AUTOSAR XML (schema 4-2-2)
package /STELLANTIS/EPT/ASWCs
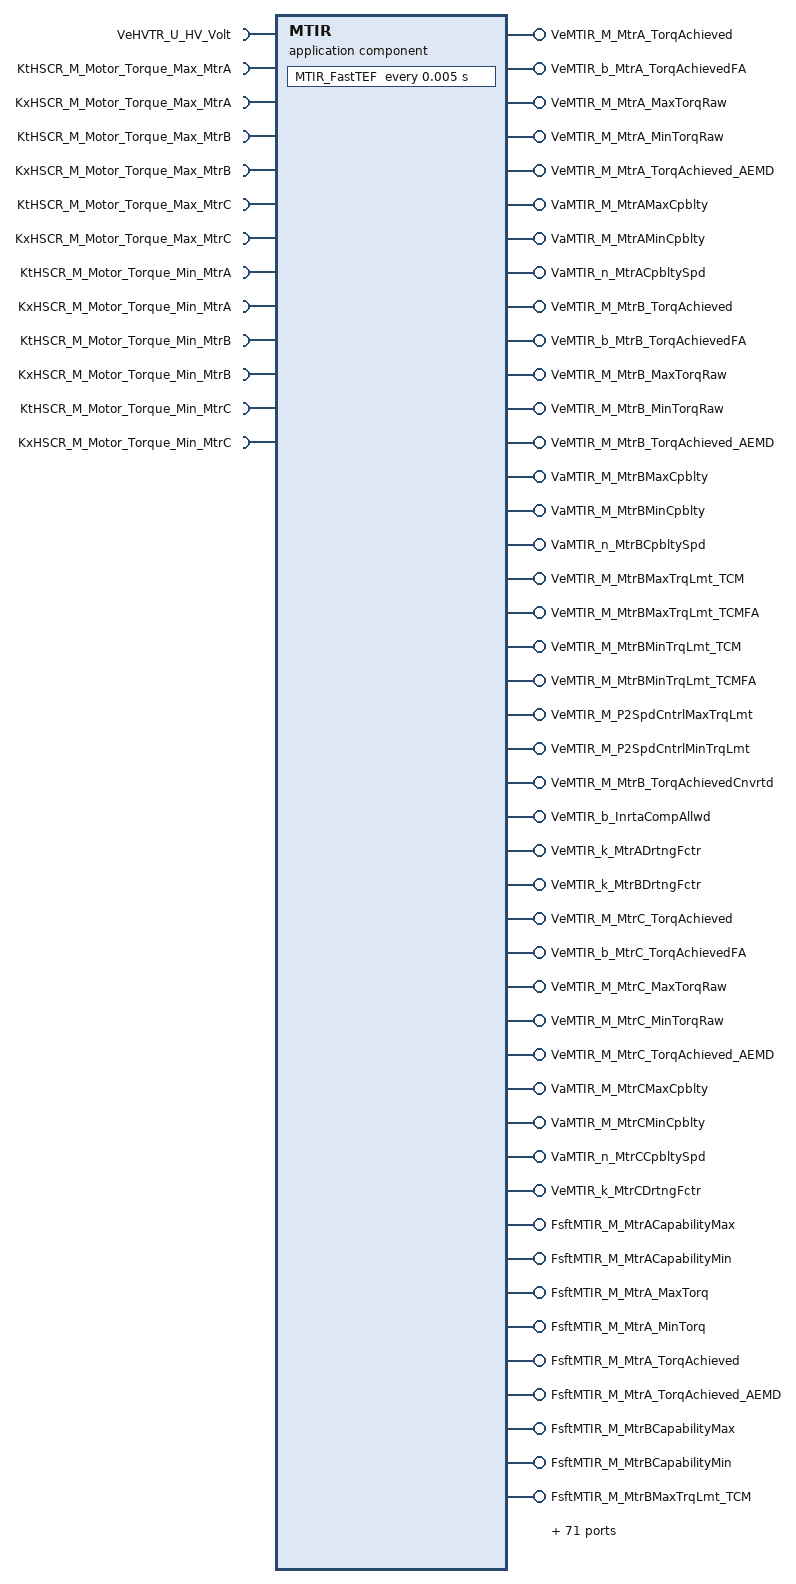
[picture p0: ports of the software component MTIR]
  application sw component type MTIR
    require port VeHVTR_U_HV_Volt: nonqueued-receiver-com-spec{data-element=Value, init-value=0}, required-interface=VeHVTR_U_HV_Volt
    115 x provide port:
      VeMTIR_M_MtrA_TorqAchieved: nonqueued-sender-com-spec{data-element=Value, init-value=0}, provided-interface=VeMTIR_M_MtrA_TorqAchieved
      VeMTIR_b_MtrA_TorqAchievedFA: nonqueued-sender-com-spec{data-element=Value, init-value=0}, provided-interface=VeMTIR_b_MtrA_TorqAchievedFA
      VeMTIR_M_MtrA_MaxTorqRaw: nonqueued-sender-com-spec{data-element=Value, init-value=0}, provided-interface=VeMTIR_M_MtrA_MaxTorqRaw
      VeMTIR_M_MtrA_MinTorqRaw: nonqueued-sender-com-spec{data-element=Value, init-value=0}, provided-interface=VeMTIR_M_MtrA_MinTorqRaw
      VeMTIR_M_MtrA_TorqAchieved_AEMD: nonqueued-sender-com-spec{data-element=Value, init-value=0}, provided-interface=VeMTIR_M_MtrA_TorqAchieved_AEMD
      VaMTIR_M_MtrAMaxCpblty: nonqueued-sender-com-spec{data-element=Value, init-value=16 x 0}, provided-interface=VaMTIR_M_MtrAMaxCpblty
      VaMTIR_M_MtrAMinCpblty: nonqueued-sender-com-spec{data-element=Value, init-value=16 x 0}, provided-interface=VaMTIR_M_MtrAMinCpblty
      VaMTIR_n_MtrACpbltySpd: nonqueued-sender-com-spec{data-element=Value, init-value=16 x 0}, provided-interface=VaMTIR_n_MtrACpbltySpd
      VeMTIR_M_MtrB_TorqAchieved: nonqueued-sender-com-spec{data-element=Value, init-value=0}, provided-interface=VeMTIR_M_MtrB_TorqAchieved
      VeMTIR_b_MtrB_TorqAchievedFA: nonqueued-sender-com-spec{data-element=Value, init-value=0}, provided-interface=VeMTIR_b_MtrB_TorqAchievedFA
      VeMTIR_M_MtrB_MaxTorqRaw: nonqueued-sender-com-spec{data-element=Value, init-value=0}, provided-interface=VeMTIR_M_MtrB_MaxTorqRaw
      VeMTIR_M_MtrB_MinTorqRaw: nonqueued-sender-com-spec{data-element=Value, init-value=0}, provided-interface=VeMTIR_M_MtrB_MinTorqRaw
      VeMTIR_M_MtrB_TorqAchieved_AEMD: nonqueued-sender-com-spec{data-element=Value, init-value=0}, provided-interface=VeMTIR_M_MtrB_TorqAchieved_AEMD
      VaMTIR_M_MtrBMaxCpblty: nonqueued-sender-com-spec{data-element=Value, init-value=16 x 0}, provided-interface=VaMTIR_M_MtrBMaxCpblty
      VaMTIR_M_MtrBMinCpblty: nonqueued-sender-com-spec{data-element=Value, init-value=16 x 0}, provided-interface=VaMTIR_M_MtrBMinCpblty
      VaMTIR_n_MtrBCpbltySpd: nonqueued-sender-com-spec{data-element=Value, init-value=16 x 0}, provided-interface=VaMTIR_n_MtrBCpbltySpd
      VeMTIR_M_MtrBMaxTrqLmt_TCM: nonqueued-sender-com-spec{data-element=Value, init-value=0}, provided-interface=VeMTIR_M_MtrBMaxTrqLmt_TCM
      VeMTIR_M_MtrBMaxTrqLmt_TCMFA: nonqueued-sender-com-spec{data-element=Value, init-value=0}, provided-interface=VeMTIR_M_MtrBMaxTrqLmt_TCMFA
      VeMTIR_M_MtrBMinTrqLmt_TCM: nonqueued-sender-com-spec{data-element=Value, init-value=0}, provided-interface=VeMTIR_M_MtrBMinTrqLmt_TCM
      VeMTIR_M_MtrBMinTrqLmt_TCMFA: nonqueued-sender-com-spec{data-element=Value, init-value=0}, provided-interface=VeMTIR_M_MtrBMinTrqLmt_TCMFA
      VeMTIR_M_P2SpdCntrlMaxTrqLmt: nonqueued-sender-com-spec{data-element=Value, init-value=0}, provided-interface=VeMTIR_M_P2SpdCntrlMaxTrqLmt
      VeMTIR_M_P2SpdCntrlMinTrqLmt: nonqueued-sender-com-spec{data-element=Value, init-value=0}, provided-interface=VeMTIR_M_P2SpdCntrlMinTrqLmt
      VeMTIR_M_MtrB_TorqAchievedCnvrtd: nonqueued-sender-com-spec{data-element=Value, init-value=0}, provided-interface=VeMTIR_M_MtrB_TorqAchievedCnvrtd
      VeMTIR_b_InrtaCompAllwd: nonqueued-sender-com-spec{data-element=Value, init-value=0}, provided-interface=VeMTIR_b_InrtaCompAllwd
      VeMTIR_k_MtrADrtngFctr: nonqueued-sender-com-spec{data-element=Value, init-value=0}, provided-interface=VeMTIR_k_MtrADrtngFctr
      VeMTIR_k_MtrBDrtngFctr: nonqueued-sender-com-spec{data-element=Value, init-value=0}, provided-interface=VeMTIR_k_MtrBDrtngFctr
      VeMTIR_M_MtrC_TorqAchieved: nonqueued-sender-com-spec{data-element=Value, init-value=0}, provided-interface=VeMTIR_M_MtrC_TorqAchieved
      VeMTIR_b_MtrC_TorqAchievedFA: nonqueued-sender-com-spec{data-element=Value, init-value=0}, provided-interface=VeMTIR_b_MtrC_TorqAchievedFA
      VeMTIR_M_MtrC_MaxTorqRaw: nonqueued-sender-com-spec{data-element=Value, init-value=0}, provided-interface=VeMTIR_M_MtrC_MaxTorqRaw
      VeMTIR_M_MtrC_MinTorqRaw: nonqueued-sender-com-spec{data-element=Value, init-value=0}, provided-interface=VeMTIR_M_MtrC_MinTorqRaw
      VeMTIR_M_MtrC_TorqAchieved_AEMD: nonqueued-sender-com-spec{data-element=Value, init-value=0}, provided-interface=VeMTIR_M_MtrC_TorqAchieved_AEMD
      VaMTIR_M_MtrCMaxCpblty: nonqueued-sender-com-spec{data-element=Value, init-value=16 x 0}, provided-interface=VaMTIR_M_MtrCMaxCpblty
      VaMTIR_M_MtrCMinCpblty: nonqueued-sender-com-spec{data-element=Value, init-value=16 x 0}, provided-interface=VaMTIR_M_MtrCMinCpblty
      VaMTIR_n_MtrCCpbltySpd: nonqueued-sender-com-spec{data-element=Value, init-value=16 x 0}, provided-interface=VaMTIR_n_MtrCCpbltySpd
      VeMTIR_k_MtrCDrtngFctr: nonqueued-sender-com-spec{data-element=Value, init-value=0}, provided-interface=VeMTIR_k_MtrCDrtngFctr
      FsftMTIR_M_MtrACapabilityMax: server-com-spec=FsftMTIR_M_MtrACapabilityMax, provided-interface=FsftMTIR_M_MtrACapabilityMax
      FsftMTIR_M_MtrACapabilityMin: server-com-spec=FsftMTIR_M_MtrACapabilityMin, provided-interface=FsftMTIR_M_MtrACapabilityMin
      FsftMTIR_M_MtrA_MaxTorq: server-com-spec=FsftMTIR_M_MtrA_MaxTorq, provided-interface=FsftMTIR_M_MtrA_MaxTorq
      FsftMTIR_M_MtrA_MinTorq: server-com-spec=FsftMTIR_M_MtrA_MinTorq, provided-interface=FsftMTIR_M_MtrA_MinTorq
      FsftMTIR_M_MtrA_TorqAchieved: server-com-spec=FsftMTIR_M_MtrA_TorqAchieved, provided-interface=FsftMTIR_M_MtrA_TorqAchieved
      FsftMTIR_M_MtrA_TorqAchieved_AEMD: server-com-spec=FsftMTIR_M_MtrA_TorqAchieved_AEMD, provided-interface=FsftMTIR_M_MtrA_TorqAchieved_AEMD
      FsftMTIR_M_MtrBCapabilityMax: server-com-spec=FsftMTIR_M_MtrBCapabilityMax, provided-interface=FsftMTIR_M_MtrBCapabilityMax
      FsftMTIR_M_MtrBCapabilityMin: server-com-spec=FsftMTIR_M_MtrBCapabilityMin, provided-interface=FsftMTIR_M_MtrBCapabilityMin
      FsftMTIR_M_MtrBMaxTrqLmt_TCM: server-com-spec=FsftMTIR_M_MtrBMaxTrqLmt_TCM, provided-interface=FsftMTIR_M_MtrBMaxTrqLmt_TCM
      FsftMTIR_M_MtrBMinTrqLmt_TCM: server-com-spec=FsftMTIR_M_MtrBMinTrqLmt_TCM, provided-interface=FsftMTIR_M_MtrBMinTrqLmt_TCM
      FsftMTIR_M_MtrB_MaxTorq: server-com-spec=FsftMTIR_M_MtrB_MaxTorq, provided-interface=FsftMTIR_M_MtrB_MaxTorq
      FsftMTIR_M_MtrB_MinTorq: server-com-spec=FsftMTIR_M_MtrB_MinTorq, provided-interface=FsftMTIR_M_MtrB_MinTorq
      FsftMTIR_M_MtrB_TorqAchieved: server-com-spec=FsftMTIR_M_MtrB_TorqAchieved, provided-interface=FsftMTIR_M_MtrB_TorqAchieved
      FsftMTIR_M_MtrB_TorqAchieved_AEMD: server-com-spec=FsftMTIR_M_MtrB_TorqAchieved_AEMD, provided-interface=FsftMTIR_M_MtrB_TorqAchieved_AEMD
      FsftMTIR_M_MtrCCapabilityMax: server-com-spec=FsftMTIR_M_MtrCCapabilityMax, provided-interface=FsftMTIR_M_MtrCCapabilityMax
      FsftMTIR_M_MtrCCapabilityMin: server-com-spec=FsftMTIR_M_MtrCCapabilityMin, provided-interface=FsftMTIR_M_MtrCCapabilityMin
      FsftMTIR_M_MtrC_MaxTorq: server-com-spec=FsftMTIR_M_MtrC_MaxTorq, provided-interface=FsftMTIR_M_MtrC_MaxTorq
      FsftMTIR_M_MtrC_MinTorq: server-com-spec=FsftMTIR_M_MtrC_MinTorq, provided-interface=FsftMTIR_M_MtrC_MinTorq
      FsftMTIR_M_MtrC_TorqAchieved: server-com-spec=FsftMTIR_M_MtrC_TorqAchieved, provided-interface=FsftMTIR_M_MtrC_TorqAchieved
      FsftMTIR_M_MtrC_TorqAchieved_AEMD: server-com-spec=FsftMTIR_M_MtrC_TorqAchieved_AEMD, provided-interface=FsftMTIR_M_MtrC_TorqAchieved_AEMD
      FsftMTIR_M_P2SpdCntrlMaxTrqLmt: server-com-spec=FsftMTIR_M_P2SpdCntrlMaxTrqLmt, provided-interface=FsftMTIR_M_P2SpdCntrlMaxTrqLmt
      FsftMTIR_M_P2SpdCntrlMinTrqLmt: server-com-spec=FsftMTIR_M_P2SpdCntrlMinTrqLmt, provided-interface=FsftMTIR_M_P2SpdCntrlMinTrqLmt
      FsftMTIR_k_MtrADeratingFactor: server-com-spec=FsftMTIR_k_MtrADeratingFactor, provided-interface=FsftMTIR_k_MtrADeratingFactor
      FsftMTIR_k_MtrBDeratingFactor: server-com-spec=FsftMTIR_k_MtrBDeratingFactor, provided-interface=FsftMTIR_k_MtrBDeratingFactor
      FsftMTIR_k_MtrCDeratingFactor: server-com-spec=FsftMTIR_k_MtrCDeratingFactor, provided-interface=FsftMTIR_k_MtrCDeratingFactor
      FsftMTIR_n_MtrACapabilitySpd: server-com-spec=FsftMTIR_n_MtrACapabilitySpd, provided-interface=FsftMTIR_n_MtrACapabilitySpd
      FsftMTIR_n_MtrBCapabilitySpd: server-com-spec=FsftMTIR_n_MtrBCapabilitySpd, provided-interface=FsftMTIR_n_MtrBCapabilitySpd
      FsftMTIR_n_MtrCCapabilitySpd: server-com-spec=FsftMTIR_n_MtrCCapabilitySpd, provided-interface=FsftMTIR_n_MtrCCapabilitySpd
      PokeMTIR_M_MtrACapabilityMax: server-com-spec{operation=PokeMTIR_M_MtrACapabilityMax, queue-length=1}, provided-interface=PokeMTIR_M_MtrACapabilityMax
      PokeMTIR_M_MtrACapabilityMin: server-com-spec{operation=PokeMTIR_M_MtrACapabilityMin, queue-length=1}, provided-interface=PokeMTIR_M_MtrACapabilityMin
      PokeMTIR_M_MtrA_MaxTorq: server-com-spec{operation=PokeMTIR_M_MtrA_MaxTorq, queue-length=1}, provided-interface=PokeMTIR_M_MtrA_MaxTorq
      PokeMTIR_M_MtrA_MinTorq: server-com-spec{operation=PokeMTIR_M_MtrA_MinTorq, queue-length=1}, provided-interface=PokeMTIR_M_MtrA_MinTorq
      PokeMTIR_M_MtrA_TorqAchieved: server-com-spec{operation=PokeMTIR_M_MtrA_TorqAchieved, queue-length=1}, provided-interface=PokeMTIR_M_MtrA_TorqAchieved
      PokeMTIR_M_MtrA_TorqAchieved_AEMD: server-com-spec{operation=PokeMTIR_M_MtrA_TorqAchieved_AEMD, queue-length=1}, provided-interface=PokeMTIR_M_MtrA_TorqAchieved_AEMD
      PokeMTIR_M_MtrBCapabilityMax: server-com-spec{operation=PokeMTIR_M_MtrBCapabilityMax, queue-length=1}, provided-interface=PokeMTIR_M_MtrBCapabilityMax
      PokeMTIR_M_MtrBCapabilityMin: server-com-spec{operation=PokeMTIR_M_MtrBCapabilityMin, queue-length=1}, provided-interface=PokeMTIR_M_MtrBCapabilityMin
      PokeMTIR_M_MtrBMaxTrqLmt_TCM: server-com-spec{operation=PokeMTIR_M_MtrBMaxTrqLmt_TCM, queue-length=1}, provided-interface=PokeMTIR_M_MtrBMaxTrqLmt_TCM
      PokeMTIR_M_MtrBMinTrqLmt_TCM: server-com-spec{operation=PokeMTIR_M_MtrBMinTrqLmt_TCM, queue-length=1}, provided-interface=PokeMTIR_M_MtrBMinTrqLmt_TCM
      PokeMTIR_M_MtrB_MaxTorq: server-com-spec{operation=PokeMTIR_M_MtrB_MaxTorq, queue-length=1}, provided-interface=PokeMTIR_M_MtrB_MaxTorq
      PokeMTIR_M_MtrB_MinTorq: server-com-spec{operation=PokeMTIR_M_MtrB_MinTorq, queue-length=1}, provided-interface=PokeMTIR_M_MtrB_MinTorq
      PokeMTIR_M_MtrB_TorqAchieved: server-com-spec{operation=PokeMTIR_M_MtrB_TorqAchieved, queue-length=1}, provided-interface=PokeMTIR_M_MtrB_TorqAchieved
      PokeMTIR_M_MtrB_TorqAchieved_AEMD: server-com-spec{operation=PokeMTIR_M_MtrB_TorqAchieved_AEMD, queue-length=1}, provided-interface=PokeMTIR_M_MtrB_TorqAchieved_AEMD
      PokeMTIR_M_MtrCCapabilityMax: server-com-spec{operation=PokeMTIR_M_MtrCCapabilityMax, queue-length=1}, provided-interface=PokeMTIR_M_MtrCCapabilityMax
      PokeMTIR_M_MtrCCapabilityMin: server-com-spec{operation=PokeMTIR_M_MtrCCapabilityMin, queue-length=1}, provided-interface=PokeMTIR_M_MtrCCapabilityMin
      PokeMTIR_M_MtrC_MaxTorq: server-com-spec{operation=PokeMTIR_M_MtrC_MaxTorq, queue-length=1}, provided-interface=PokeMTIR_M_MtrC_MaxTorq
      PokeMTIR_M_MtrC_MinTorq: server-com-spec{operation=PokeMTIR_M_MtrC_MinTorq, queue-length=1}, provided-interface=PokeMTIR_M_MtrC_MinTorq
      PokeMTIR_M_MtrC_TorqAchieved: server-com-spec{operation=PokeMTIR_M_MtrC_TorqAchieved, queue-length=1}, provided-interface=PokeMTIR_M_MtrC_TorqAchieved
      PokeMTIR_M_MtrC_TorqAchieved_AEMD: server-com-spec{operation=PokeMTIR_M_MtrC_TorqAchieved_AEMD, queue-length=1}, provided-interface=PokeMTIR_M_MtrC_TorqAchieved_AEMD
      PokeMTIR_M_P2SpdCntrlMaxTrqLmt: server-com-spec{operation=PokeMTIR_M_P2SpdCntrlMaxTrqLmt, queue-length=1}, provided-interface=PokeMTIR_M_P2SpdCntrlMaxTrqLmt
      PokeMTIR_M_P2SpdCntrlMinTrqLmt: server-com-spec{operation=PokeMTIR_M_P2SpdCntrlMinTrqLmt, queue-length=1}, provided-interface=PokeMTIR_M_P2SpdCntrlMinTrqLmt
      PokeMTIR_k_MtrADeratingFactor: server-com-spec{operation=PokeMTIR_k_MtrADeratingFactor, queue-length=1}, provided-interface=PokeMTIR_k_MtrADeratingFactor
      PokeMTIR_k_MtrBDeratingFactor: server-com-spec{operation=PokeMTIR_k_MtrBDeratingFactor, queue-length=1}, provided-interface=PokeMTIR_k_MtrBDeratingFactor
      PokeMTIR_k_MtrCDeratingFactor: server-com-spec{operation=PokeMTIR_k_MtrCDeratingFactor, queue-length=1}, provided-interface=PokeMTIR_k_MtrCDeratingFactor
      PokeMTIR_n_MtrACapabilitySpd: server-com-spec{operation=PokeMTIR_n_MtrACapabilitySpd, queue-length=1}, provided-interface=PokeMTIR_n_MtrACapabilitySpd
      PokeMTIR_n_MtrBCapabilitySpd: server-com-spec{operation=PokeMTIR_n_MtrBCapabilitySpd, queue-length=1}, provided-interface=PokeMTIR_n_MtrBCapabilitySpd
      PokeMTIR_n_MtrCCapabilitySpd: server-com-spec{operation=PokeMTIR_n_MtrCCapabilitySpd, queue-length=1}, provided-interface=PokeMTIR_n_MtrCCapabilitySpd
      TmotMTIR_M_MtrACapabilityMax: server-com-spec=TmotMTIR_M_MtrACapabilityMax, provided-interface=TmotMTIR_M_MtrACapabilityMax
      TmotMTIR_M_MtrACapabilityMin: server-com-spec=TmotMTIR_M_MtrACapabilityMin, provided-interface=TmotMTIR_M_MtrACapabilityMin
      TmotMTIR_M_MtrBCapabilityMax: server-com-spec=TmotMTIR_M_MtrBCapabilityMax, provided-interface=TmotMTIR_M_MtrBCapabilityMax
      TmotMTIR_M_MtrBCapabilityMin: server-com-spec=TmotMTIR_M_MtrBCapabilityMin, provided-interface=TmotMTIR_M_MtrBCapabilityMin
      TmotMTIR_M_MtrCCapabilityMax: server-com-spec=TmotMTIR_M_MtrCCapabilityMax, provided-interface=TmotMTIR_M_MtrCCapabilityMax
      TmotMTIR_M_MtrCCapabilityMin: server-com-spec=TmotMTIR_M_MtrCCapabilityMin, provided-interface=TmotMTIR_M_MtrCCapabilityMin
      TmotMTIR_b_MtrA_MaxTorq: server-com-spec=TmotMTIR_b_MtrA_MaxTorq, provided-interface=TmotMTIR_b_MtrA_MaxTorq
      TmotMTIR_b_MtrA_MinTorq: server-com-spec=TmotMTIR_b_MtrA_MinTorq, provided-interface=TmotMTIR_b_MtrA_MinTorq
      TmotMTIR_b_MtrA_TorqAchieved: server-com-spec=TmotMTIR_b_MtrA_TorqAchieved, provided-interface=TmotMTIR_b_MtrA_TorqAchieved
      TmotMTIR_b_MtrA_TorqAchieved_AEMD: server-com-spec=TmotMTIR_b_MtrA_TorqAchieved_AEMD, provided-interface=TmotMTIR_b_MtrA_TorqAchieved_AEMD
      TmotMTIR_b_MtrB_MaxTorq: server-com-spec=TmotMTIR_b_MtrB_MaxTorq, provided-interface=TmotMTIR_b_MtrB_MaxTorq
      TmotMTIR_b_MtrB_MinTorq: server-com-spec=TmotMTIR_b_MtrB_MinTorq, provided-interface=TmotMTIR_b_MtrB_MinTorq
      TmotMTIR_b_MtrB_TorqAchieved: server-com-spec=TmotMTIR_b_MtrB_TorqAchieved, provided-interface=TmotMTIR_b_MtrB_TorqAchieved
      TmotMTIR_b_MtrB_TorqAchieved_AEMD: server-com-spec=TmotMTIR_b_MtrB_TorqAchieved_AEMD, provided-interface=TmotMTIR_b_MtrB_TorqAchieved_AEMD
      TmotMTIR_b_MtrC_MaxTorq: server-com-spec=TmotMTIR_b_MtrC_MaxTorq, provided-interface=TmotMTIR_b_MtrC_MaxTorq
      TmotMTIR_b_MtrC_MinTorq: server-com-spec=TmotMTIR_b_MtrC_MinTorq, provided-interface=TmotMTIR_b_MtrC_MinTorq
      TmotMTIR_b_MtrC_TorqAchieved: server-com-spec=TmotMTIR_b_MtrC_TorqAchieved, provided-interface=TmotMTIR_b_MtrC_TorqAchieved
      TmotMTIR_b_MtrC_TorqAchieved_AEMD: server-com-spec=TmotMTIR_b_MtrC_TorqAchieved_AEMD, provided-interface=TmotMTIR_b_MtrC_TorqAchieved_AEMD
      TmotMTIR_k_MtrADeratingFactor: server-com-spec=TmotMTIR_k_MtrADeratingFactor, provided-interface=TmotMTIR_k_MtrADeratingFactor
      TmotMTIR_k_MtrBDeratingFactor: server-com-spec=TmotMTIR_k_MtrBDeratingFactor, provided-interface=TmotMTIR_k_MtrBDeratingFactor
      TmotMTIR_k_MtrCDeratingFactor: server-com-spec=TmotMTIR_k_MtrCDeratingFactor, provided-interface=TmotMTIR_k_MtrCDeratingFactor
      TmotMTIR_n_MtrACapabilitySpd: server-com-spec=TmotMTIR_n_MtrACapabilitySpd, provided-interface=TmotMTIR_n_MtrACapabilitySpd
      TmotMTIR_n_MtrBCapabilitySpd: server-com-spec=TmotMTIR_n_MtrBCapabilitySpd, provided-interface=TmotMTIR_n_MtrBCapabilitySpd
      TmotMTIR_n_MtrCCapabilitySpd: server-com-spec=TmotMTIR_n_MtrCCapabilitySpd, provided-interface=TmotMTIR_n_MtrCCapabilitySpd
    12 x require port:
      KtHSCR_M_Motor_Torque_Max_MtrA: parameter-require-com-spec{init-value=[252 252 252 252 252 252 244.990005493164 201.789993286133 165.270004272461 139.75 120.849998474121 105.48999786377 94.379997253418 84.9199981689453 76.5400009155273 70.5100021362305 65.2399978637695 60.5299987792969 56.2400016784668 52.3600006103516 49.0099983215332 46], parameter=KtHSCR_M_Motor_Torque_Max_MtrA}, required-interface=KtHSCR_M_Motor_Torque_Max_MtrA
      KxHSCR_M_Motor_Torque_Max_MtrA: parameter-require-com-spec{init-value=[0.00999999977648258 500 1000 1500 2000 2500 3000 3500 4000 4500 5000 5500 6000 6500 7000 7500 8000 8500 9000 9500 10000 10500], parameter=KxHSCR_M_Motor_Torque_Max_MtrA}, required-interface=KxHSCR_M_Motor_Torque_Max_MtrA
      KtHSCR_M_Motor_Torque_Max_MtrB: parameter-require-com-spec{init-value=[252 252 252 252 252 252 244.990005493164 201.789993286133 165.270004272461 139.75 120.849998474121 105.48999786377 94.379997253418 84.9199981689453 76.5400009155273 70.5100021362305 65.2399978637695 60.5299987792969 56.2400016784668 52.3600006103516 49.0099983215332 46], parameter=KtHSCR_M_Motor_Torque_Max_MtrB}, required-interface=KtHSCR_M_Motor_Torque_Max_MtrB
      KxHSCR_M_Motor_Torque_Max_MtrB: parameter-require-com-spec{init-value=[0.00999999977648258 500 1000 1500 2000 2500 3000 3500 4000 4500 5000 5500 6000 6500 7000 7500 8000 8500 9000 9500 10000 10500], parameter=KxHSCR_M_Motor_Torque_Max_MtrB}, required-interface=KxHSCR_M_Motor_Torque_Max_MtrB
      KtHSCR_M_Motor_Torque_Max_MtrC: parameter-require-com-spec{init-value=[252 252 252 252 252 252 244.990005493164 201.789993286133 165.270004272461 139.75 120.849998474121 105.48999786377 94.379997253418 84.9199981689453 76.5400009155273 70.5100021362305 65.2399978637695 60.5299987792969 56.2400016784668 52.3600006103516 49.0099983215332 46], parameter=KtHSCR_M_Motor_Torque_Max_MtrC}, required-interface=KtHSCR_M_Motor_Torque_Max_MtrC
      KxHSCR_M_Motor_Torque_Max_MtrC: parameter-require-com-spec{init-value=[0.00999999977648258 500 1000 1500 2000 2500 3000 3500 4000 4500 5000 5500 6000 6500 7000 7500 8000 8500 9000 9500 10000 10500], parameter=KxHSCR_M_Motor_Torque_Max_MtrC}, required-interface=KxHSCR_M_Motor_Torque_Max_MtrC
      KtHSCR_M_Motor_Torque_Min_MtrA: parameter-require-com-spec{init-value=[-252 -252 -252 -252 -252 -252 -252 -238.029998779297 -205.229995727539 -175.800003051758 -152.279998779297 -133.940002441406 -119.400001525879 -107.589996337891 -97.8499984741211 -89.6699981689453 -82.7399978637695 -76.7900009155273 -71.629997253418 -67.1100006103516 -63.0999984741211 -60], parameter=KtHSCR_M_Motor_Torque_Min_MtrA}, required-interface=KtHSCR_M_Motor_Torque_Min_MtrA
      KxHSCR_M_Motor_Torque_Min_MtrA: parameter-require-com-spec{init-value=[0.00999999977648258 500 1000 1500 2000 2500 3000 3500 4000 4500 5000 5500 6000 6500 7000 7500 8000 8500 9000 9500 10000 10500], parameter=KxHSCR_M_Motor_Torque_Min_MtrA}, required-interface=KxHSCR_M_Motor_Torque_Min_MtrA
      KtHSCR_M_Motor_Torque_Min_MtrB: parameter-require-com-spec{init-value=[-252 -252 -252 -252 -252 -252 -252 -238.029998779297 -205.229995727539 -175.800003051758 -152.279998779297 -133.940002441406 -119.400001525879 -107.589996337891 -97.8499984741211 -89.6699981689453 -82.7399978637695 -76.7900009155273 -71.629997253418 -67.1100006103516 -63.0999984741211 -60], parameter=KtHSCR_M_Motor_Torque_Min_MtrB}, required-interface=KtHSCR_M_Motor_Torque_Min_MtrB
      KxHSCR_M_Motor_Torque_Min_MtrB: parameter-require-com-spec{init-value=[0.00999999977648258 500 1000 1500 2000 2500 3000 3500 4000 4500 5000 5500 6000 6500 7000 7500 8000 8500 9000 9500 10000 10500], parameter=KxHSCR_M_Motor_Torque_Min_MtrB}, required-interface=KxHSCR_M_Motor_Torque_Min_MtrB
      KtHSCR_M_Motor_Torque_Min_MtrC: parameter-require-com-spec{init-value=[-252 -252 -252 -252 -252 -252 -252 -238.029998779297 -205.229995727539 -175.800003051758 -152.279998779297 -133.940002441406 -119.400001525879 -107.589996337891 -97.8499984741211 -89.6699981689453 -82.7399978637695 -76.7900009155273 -71.629997253418 -67.1100006103516 -63.0999984741211 -60], parameter=KtHSCR_M_Motor_Torque_Min_MtrC}, required-interface=KtHSCR_M_Motor_Torque_Min_MtrC
      KxHSCR_M_Motor_Torque_Min_MtrC: parameter-require-com-spec{init-value=[0.00999999977648258 500 1000 1500 2000 2500 3000 3500 4000 4500 5000 5500 6000 6500 7000 7500 8000 8500 9000 9500 10000 10500], parameter=KxHSCR_M_Motor_Torque_Min_MtrC}, required-interface=KxHSCR_M_Motor_Torque_Min_MtrC
    behavior IB_MTIR: data-type-mapping=msADTtoIDTMapping, handle-termination-and-restart=NO-SUPPORT
      timing event Event_FastTEF: start-on-event=MTIR_FastTEF, period=0.005
      80 x operation invoked event:
        Event_FsftMTIR_M_MtrACapabilityMax: start-on-event=FsftMTIR_M_MtrACapabilityMax, operation=FsftMTIR_M_MtrACapabilityMax.FsftMTIR_M_MtrACapabilityMax
        Event_FsftMTIR_M_MtrACapabilityMin: start-on-event=FsftMTIR_M_MtrACapabilityMin, operation=FsftMTIR_M_MtrACapabilityMin.FsftMTIR_M_MtrACapabilityMin
        Event_FsftMTIR_M_MtrA_MaxTorq: start-on-event=FsftMTIR_M_MtrA_MaxTorq, operation=FsftMTIR_M_MtrA_MaxTorq.FsftMTIR_M_MtrA_MaxTorq
        Event_FsftMTIR_M_MtrA_MinTorq: start-on-event=FsftMTIR_M_MtrA_MinTorq, operation=FsftMTIR_M_MtrA_MinTorq.FsftMTIR_M_MtrA_MinTorq
        Event_FsftMTIR_M_MtrA_TorqAchieved: start-on-event=FsftMTIR_M_MtrA_TorqAchieved, operation=FsftMTIR_M_MtrA_TorqAchieved.FsftMTIR_M_MtrA_TorqAchieved
        Event_FsftMTIR_M_MtrA_TorqAchieved_AEMD: start-on-event=FsftMTIR_M_MtrA_TorqAchieved_AEMD, operation=FsftMTIR_M_MtrA_TorqAchieved_AEMD.FsftMTIR_M_MtrA_TorqAchieved_AEMD
        Event_FsftMTIR_M_MtrBCapabilityMax: start-on-event=FsftMTIR_M_MtrBCapabilityMax, operation=FsftMTIR_M_MtrBCapabilityMax.FsftMTIR_M_MtrBCapabilityMax
        Event_FsftMTIR_M_MtrBCapabilityMin: start-on-event=FsftMTIR_M_MtrBCapabilityMin, operation=FsftMTIR_M_MtrBCapabilityMin.FsftMTIR_M_MtrBCapabilityMin
        Event_FsftMTIR_M_MtrBMaxTrqLmt_TCM: start-on-event=FsftMTIR_M_MtrBMaxTrqLmt_TCM, operation=FsftMTIR_M_MtrBMaxTrqLmt_TCM.FsftMTIR_M_MtrBMaxTrqLmt_TCM
        Event_FsftMTIR_M_MtrBMinTrqLmt_TCM: start-on-event=FsftMTIR_M_MtrBMinTrqLmt_TCM, operation=FsftMTIR_M_MtrBMinTrqLmt_TCM.FsftMTIR_M_MtrBMinTrqLmt_TCM
        Event_FsftMTIR_M_MtrB_MaxTorq: start-on-event=FsftMTIR_M_MtrB_MaxTorq, operation=FsftMTIR_M_MtrB_MaxTorq.FsftMTIR_M_MtrB_MaxTorq
        Event_FsftMTIR_M_MtrB_MinTorq: start-on-event=FsftMTIR_M_MtrB_MinTorq, operation=FsftMTIR_M_MtrB_MinTorq.FsftMTIR_M_MtrB_MinTorq
        Event_FsftMTIR_M_MtrB_TorqAchieved: start-on-event=FsftMTIR_M_MtrB_TorqAchieved, operation=FsftMTIR_M_MtrB_TorqAchieved.FsftMTIR_M_MtrB_TorqAchieved
        Event_FsftMTIR_M_MtrB_TorqAchieved_AEMD: start-on-event=FsftMTIR_M_MtrB_TorqAchieved_AEMD, operation=FsftMTIR_M_MtrB_TorqAchieved_AEMD.FsftMTIR_M_MtrB_TorqAchieved_AEMD
        Event_FsftMTIR_M_MtrCCapabilityMax: start-on-event=FsftMTIR_M_MtrCCapabilityMax, operation=FsftMTIR_M_MtrCCapabilityMax.FsftMTIR_M_MtrCCapabilityMax
        Event_FsftMTIR_M_MtrCCapabilityMin: start-on-event=FsftMTIR_M_MtrCCapabilityMin, operation=FsftMTIR_M_MtrCCapabilityMin.FsftMTIR_M_MtrCCapabilityMin
        Event_FsftMTIR_M_MtrC_MaxTorq: start-on-event=FsftMTIR_M_MtrC_MaxTorq, operation=FsftMTIR_M_MtrC_MaxTorq.FsftMTIR_M_MtrC_MaxTorq
        Event_FsftMTIR_M_MtrC_MinTorq: start-on-event=FsftMTIR_M_MtrC_MinTorq, operation=FsftMTIR_M_MtrC_MinTorq.FsftMTIR_M_MtrC_MinTorq
        Event_FsftMTIR_M_MtrC_TorqAchieved: start-on-event=FsftMTIR_M_MtrC_TorqAchieved, operation=FsftMTIR_M_MtrC_TorqAchieved.FsftMTIR_M_MtrC_TorqAchieved
        Event_FsftMTIR_M_MtrC_TorqAchieved_AEMD: start-on-event=FsftMTIR_M_MtrC_TorqAchieved_AEMD, operation=FsftMTIR_M_MtrC_TorqAchieved_AEMD.FsftMTIR_M_MtrC_TorqAchieved_AEMD
        Event_FsftMTIR_M_P2SpdCntrlMaxTrqLmt: start-on-event=FsftMTIR_M_P2SpdCntrlMaxTrqLmt, operation=FsftMTIR_M_P2SpdCntrlMaxTrqLmt.FsftMTIR_M_P2SpdCntrlMaxTrqLmt
        Event_FsftMTIR_M_P2SpdCntrlMinTrqLmt: start-on-event=FsftMTIR_M_P2SpdCntrlMinTrqLmt, operation=FsftMTIR_M_P2SpdCntrlMinTrqLmt.FsftMTIR_M_P2SpdCntrlMinTrqLmt
        Event_FsftMTIR_k_MtrADeratingFactor: start-on-event=FsftMTIR_k_MtrADeratingFactor, operation=FsftMTIR_k_MtrADeratingFactor.FsftMTIR_k_MtrADeratingFactor
        Event_FsftMTIR_k_MtrBDeratingFactor: start-on-event=FsftMTIR_k_MtrBDeratingFactor, operation=FsftMTIR_k_MtrBDeratingFactor.FsftMTIR_k_MtrBDeratingFactor
        Event_FsftMTIR_k_MtrCDeratingFactor: start-on-event=FsftMTIR_k_MtrCDeratingFactor, operation=FsftMTIR_k_MtrCDeratingFactor.FsftMTIR_k_MtrCDeratingFactor
        Event_FsftMTIR_n_MtrACapabilitySpd: start-on-event=FsftMTIR_n_MtrACapabilitySpd, operation=FsftMTIR_n_MtrACapabilitySpd.FsftMTIR_n_MtrACapabilitySpd
        Event_FsftMTIR_n_MtrBCapabilitySpd: start-on-event=FsftMTIR_n_MtrBCapabilitySpd, operation=FsftMTIR_n_MtrBCapabilitySpd.FsftMTIR_n_MtrBCapabilitySpd
        Event_FsftMTIR_n_MtrCCapabilitySpd: start-on-event=FsftMTIR_n_MtrCCapabilitySpd, operation=FsftMTIR_n_MtrCCapabilitySpd.FsftMTIR_n_MtrCCapabilitySpd
        Event_PokeMTIR_M_MtrACapabilityMax: start-on-event=PokeMTIR_M_MtrACapabilityMax, operation=PokeMTIR_M_MtrACapabilityMax.PokeMTIR_M_MtrACapabilityMax
        Event_PokeMTIR_M_MtrACapabilityMin: start-on-event=PokeMTIR_M_MtrACapabilityMin, operation=PokeMTIR_M_MtrACapabilityMin.PokeMTIR_M_MtrACapabilityMin
        Event_PokeMTIR_M_MtrA_MaxTorq: start-on-event=PokeMTIR_M_MtrA_MaxTorq, operation=PokeMTIR_M_MtrA_MaxTorq.PokeMTIR_M_MtrA_MaxTorq
        Event_PokeMTIR_M_MtrA_MinTorq: start-on-event=PokeMTIR_M_MtrA_MinTorq, operation=PokeMTIR_M_MtrA_MinTorq.PokeMTIR_M_MtrA_MinTorq
        Event_PokeMTIR_M_MtrA_TorqAchieved: start-on-event=PokeMTIR_M_MtrA_TorqAchieved, operation=PokeMTIR_M_MtrA_TorqAchieved.PokeMTIR_M_MtrA_TorqAchieved
        Event_PokeMTIR_M_MtrA_TorqAchieved_AEMD: start-on-event=PokeMTIR_M_MtrA_TorqAchieved_AEMD, operation=PokeMTIR_M_MtrA_TorqAchieved_AEMD.PokeMTIR_M_MtrA_TorqAchieved_AEMD
        Event_PokeMTIR_M_MtrBCapabilityMax: start-on-event=PokeMTIR_M_MtrBCapabilityMax, operation=PokeMTIR_M_MtrBCapabilityMax.PokeMTIR_M_MtrBCapabilityMax
        Event_PokeMTIR_M_MtrBCapabilityMin: start-on-event=PokeMTIR_M_MtrBCapabilityMin, operation=PokeMTIR_M_MtrBCapabilityMin.PokeMTIR_M_MtrBCapabilityMin
        Event_PokeMTIR_M_MtrBMaxTrqLmt_TCM: start-on-event=PokeMTIR_M_MtrBMaxTrqLmt_TCM, operation=PokeMTIR_M_MtrBMaxTrqLmt_TCM.PokeMTIR_M_MtrBMaxTrqLmt_TCM
        Event_PokeMTIR_M_MtrBMinTrqLmt_TCM: start-on-event=PokeMTIR_M_MtrBMinTrqLmt_TCM, operation=PokeMTIR_M_MtrBMinTrqLmt_TCM.PokeMTIR_M_MtrBMinTrqLmt_TCM
        Event_PokeMTIR_M_MtrB_MaxTorq: start-on-event=PokeMTIR_M_MtrB_MaxTorq, operation=PokeMTIR_M_MtrB_MaxTorq.PokeMTIR_M_MtrB_MaxTorq
        Event_PokeMTIR_M_MtrB_MinTorq: start-on-event=PokeMTIR_M_MtrB_MinTorq, operation=PokeMTIR_M_MtrB_MinTorq.PokeMTIR_M_MtrB_MinTorq
        Event_PokeMTIR_M_MtrB_TorqAchieved: start-on-event=PokeMTIR_M_MtrB_TorqAchieved, operation=PokeMTIR_M_MtrB_TorqAchieved.PokeMTIR_M_MtrB_TorqAchieved
        Event_PokeMTIR_M_MtrB_TorqAchieved_AEMD: start-on-event=PokeMTIR_M_MtrB_TorqAchieved_AEMD, operation=PokeMTIR_M_MtrB_TorqAchieved_AEMD.PokeMTIR_M_MtrB_TorqAchieved_AEMD
        Event_PokeMTIR_M_MtrCCapabilityMax: start-on-event=PokeMTIR_M_MtrCCapabilityMax, operation=PokeMTIR_M_MtrCCapabilityMax.PokeMTIR_M_MtrCCapabilityMax
        Event_PokeMTIR_M_MtrCCapabilityMin: start-on-event=PokeMTIR_M_MtrCCapabilityMin, operation=PokeMTIR_M_MtrCCapabilityMin.PokeMTIR_M_MtrCCapabilityMin
        Event_PokeMTIR_M_MtrC_MaxTorq: start-on-event=PokeMTIR_M_MtrC_MaxTorq, operation=PokeMTIR_M_MtrC_MaxTorq.PokeMTIR_M_MtrC_MaxTorq
        Event_PokeMTIR_M_MtrC_MinTorq: start-on-event=PokeMTIR_M_MtrC_MinTorq, operation=PokeMTIR_M_MtrC_MinTorq.PokeMTIR_M_MtrC_MinTorq
        Event_PokeMTIR_M_MtrC_TorqAchieved: start-on-event=PokeMTIR_M_MtrC_TorqAchieved, operation=PokeMTIR_M_MtrC_TorqAchieved.PokeMTIR_M_MtrC_TorqAchieved
        Event_PokeMTIR_M_MtrC_TorqAchieved_AEMD: start-on-event=PokeMTIR_M_MtrC_TorqAchieved_AEMD, operation=PokeMTIR_M_MtrC_TorqAchieved_AEMD.PokeMTIR_M_MtrC_TorqAchieved_AEMD
        Event_PokeMTIR_M_P2SpdCntrlMaxTrqLmt: start-on-event=PokeMTIR_M_P2SpdCntrlMaxTrqLmt, operation=PokeMTIR_M_P2SpdCntrlMaxTrqLmt.PokeMTIR_M_P2SpdCntrlMaxTrqLmt
        Event_PokeMTIR_M_P2SpdCntrlMinTrqLmt: start-on-event=PokeMTIR_M_P2SpdCntrlMinTrqLmt, operation=PokeMTIR_M_P2SpdCntrlMinTrqLmt.PokeMTIR_M_P2SpdCntrlMinTrqLmt
        Event_PokeMTIR_k_MtrADeratingFactor: start-on-event=PokeMTIR_k_MtrADeratingFactor, operation=PokeMTIR_k_MtrADeratingFactor.PokeMTIR_k_MtrADeratingFactor
        Event_PokeMTIR_k_MtrBDeratingFactor: start-on-event=PokeMTIR_k_MtrBDeratingFactor, operation=PokeMTIR_k_MtrBDeratingFactor.PokeMTIR_k_MtrBDeratingFactor
        Event_PokeMTIR_k_MtrCDeratingFactor: start-on-event=PokeMTIR_k_MtrCDeratingFactor, operation=PokeMTIR_k_MtrCDeratingFactor.PokeMTIR_k_MtrCDeratingFactor
        Event_PokeMTIR_n_MtrACapabilitySpd: start-on-event=PokeMTIR_n_MtrACapabilitySpd, operation=PokeMTIR_n_MtrACapabilitySpd.PokeMTIR_n_MtrACapabilitySpd
        Event_PokeMTIR_n_MtrBCapabilitySpd: start-on-event=PokeMTIR_n_MtrBCapabilitySpd, operation=PokeMTIR_n_MtrBCapabilitySpd.PokeMTIR_n_MtrBCapabilitySpd
        Event_PokeMTIR_n_MtrCCapabilitySpd: start-on-event=PokeMTIR_n_MtrCCapabilitySpd, operation=PokeMTIR_n_MtrCCapabilitySpd.PokeMTIR_n_MtrCCapabilitySpd
        Event_TmotMTIR_M_MtrACapabilityMax: start-on-event=TmotMTIR_M_MtrACapabilityMax, operation=TmotMTIR_M_MtrACapabilityMax.TmotMTIR_M_MtrACapabilityMax
        Event_TmotMTIR_M_MtrACapabilityMin: start-on-event=TmotMTIR_M_MtrACapabilityMin, operation=TmotMTIR_M_MtrACapabilityMin.TmotMTIR_M_MtrACapabilityMin
        Event_TmotMTIR_M_MtrBCapabilityMax: start-on-event=TmotMTIR_M_MtrBCapabilityMax, operation=TmotMTIR_M_MtrBCapabilityMax.TmotMTIR_M_MtrBCapabilityMax
        Event_TmotMTIR_M_MtrBCapabilityMin: start-on-event=TmotMTIR_M_MtrBCapabilityMin, operation=TmotMTIR_M_MtrBCapabilityMin.TmotMTIR_M_MtrBCapabilityMin
        Event_TmotMTIR_M_MtrCCapabilityMax: start-on-event=TmotMTIR_M_MtrCCapabilityMax, operation=TmotMTIR_M_MtrCCapabilityMax.TmotMTIR_M_MtrCCapabilityMax
        Event_TmotMTIR_M_MtrCCapabilityMin: start-on-event=TmotMTIR_M_MtrCCapabilityMin, operation=TmotMTIR_M_MtrCCapabilityMin.TmotMTIR_M_MtrCCapabilityMin
        Event_TmotMTIR_b_MtrA_MaxTorq: start-on-event=TmotMTIR_b_MtrA_MaxTorq, operation=TmotMTIR_b_MtrA_MaxTorq.TmotMTIR_b_MtrA_MaxTorq
        Event_TmotMTIR_b_MtrA_MinTorq: start-on-event=TmotMTIR_b_MtrA_MinTorq, operation=TmotMTIR_b_MtrA_MinTorq.TmotMTIR_b_MtrA_MinTorq
        Event_TmotMTIR_b_MtrA_TorqAchieved: start-on-event=TmotMTIR_b_MtrA_TorqAchieved, operation=TmotMTIR_b_MtrA_TorqAchieved.TmotMTIR_b_MtrA_TorqAchieved
        Event_TmotMTIR_b_MtrA_TorqAchieved_AEMD: start-on-event=TmotMTIR_b_MtrA_TorqAchieved_AEMD, operation=TmotMTIR_b_MtrA_TorqAchieved_AEMD.TmotMTIR_b_MtrA_TorqAchieved_AEMD
        Event_TmotMTIR_b_MtrB_MaxTorq: start-on-event=TmotMTIR_b_MtrB_MaxTorq, operation=TmotMTIR_b_MtrB_MaxTorq.TmotMTIR_b_MtrB_MaxTorq
        Event_TmotMTIR_b_MtrB_MinTorq: start-on-event=TmotMTIR_b_MtrB_MinTorq, operation=TmotMTIR_b_MtrB_MinTorq.TmotMTIR_b_MtrB_MinTorq
        Event_TmotMTIR_b_MtrB_TorqAchieved: start-on-event=TmotMTIR_b_MtrB_TorqAchieved, operation=TmotMTIR_b_MtrB_TorqAchieved.TmotMTIR_b_MtrB_TorqAchieved
        Event_TmotMTIR_b_MtrB_TorqAchieved_AEMD: start-on-event=TmotMTIR_b_MtrB_TorqAchieved_AEMD, operation=TmotMTIR_b_MtrB_TorqAchieved_AEMD.TmotMTIR_b_MtrB_TorqAchieved_AEMD
        Event_TmotMTIR_b_MtrC_MaxTorq: start-on-event=TmotMTIR_b_MtrC_MaxTorq, operation=TmotMTIR_b_MtrC_MaxTorq.TmotMTIR_b_MtrC_MaxTorq
        Event_TmotMTIR_b_MtrC_MinTorq: start-on-event=TmotMTIR_b_MtrC_MinTorq, operation=TmotMTIR_b_MtrC_MinTorq.TmotMTIR_b_MtrC_MinTorq
        Event_TmotMTIR_b_MtrC_TorqAchieved: start-on-event=TmotMTIR_b_MtrC_TorqAchieved, operation=TmotMTIR_b_MtrC_TorqAchieved.TmotMTIR_b_MtrC_TorqAchieved
        Event_TmotMTIR_b_MtrC_TorqAchieved_AEMD: start-on-event=TmotMTIR_b_MtrC_TorqAchieved_AEMD, operation=TmotMTIR_b_MtrC_TorqAchieved_AEMD.TmotMTIR_b_MtrC_TorqAchieved_AEMD
        Event_TmotMTIR_k_MtrADeratingFactor: start-on-event=TmotMTIR_k_MtrADeratingFactor, operation=TmotMTIR_k_MtrADeratingFactor.TmotMTIR_k_MtrADeratingFactor
        Event_TmotMTIR_k_MtrBDeratingFactor: start-on-event=TmotMTIR_k_MtrBDeratingFactor, operation=TmotMTIR_k_MtrBDeratingFactor.TmotMTIR_k_MtrBDeratingFactor
        Event_TmotMTIR_k_MtrCDeratingFactor: start-on-event=TmotMTIR_k_MtrCDeratingFactor, operation=TmotMTIR_k_MtrCDeratingFactor.TmotMTIR_k_MtrCDeratingFactor
        Event_TmotMTIR_n_MtrACapabilitySpd: start-on-event=TmotMTIR_n_MtrACapabilitySpd, operation=TmotMTIR_n_MtrACapabilitySpd.TmotMTIR_n_MtrACapabilitySpd
        Event_TmotMTIR_n_MtrBCapabilitySpd: start-on-event=TmotMTIR_n_MtrBCapabilitySpd, operation=TmotMTIR_n_MtrBCapabilitySpd.TmotMTIR_n_MtrBCapabilitySpd
        Event_TmotMTIR_n_MtrCCapabilitySpd: start-on-event=TmotMTIR_n_MtrCCapabilitySpd, operation=TmotMTIR_n_MtrCCapabilitySpd.TmotMTIR_n_MtrCCapabilitySpd
      init event Event_MTIR_ac_Init: start-on-event=MTIR_ac_Init
      init event Event_PwrOn: start-on-event=MTIR_PwrOn
      explicit-inter-runnable-variables:
        59 x data, all with sw-calibration-access=READ-ONLY:
          VeMTIR_M_MtrA_TorqAchieved_write_IRV: category=VALUE, type=Float, init-value=0
          VeMTIR_b_MtrA_TorqAchievedFA_write_IRV: category=VALUE, type=Boolean, init-value=0
          VeMTIR_M_MtrA_MaxTorq_write_IRV: category=VALUE, type=Float, init-value=0
          VeMTIR_b_MtrA_MaxTorqSgnl_Rcvd_write_IRV: category=VALUE, type=Boolean, init-value=0
          VeMTIR_M_MtrA_MinTorq_write_IRV: category=VALUE, type=Float, init-value=0
          VeMTIR_b_MtrA_MinTorqSgnl_Rcvd_write_IRV: category=VALUE, type=Boolean, init-value=0
          VeMTIR_M_MtrA_TorqAchieved_AEMD_write_IRV: category=VALUE, type=Float, init-value=0
          VeMTIR_b_MtrA_TorqAchieved_AEMDFA_write_IRV: category=VALUE, type=Boolean, init-value=0
          VaMTIR_M_MtrAMaxCpbltyTrq_Poke_Init_IRV: category=ARRAY, type=rt_Array_Float_16, init-value=16 x 0
          VeMTIR_b_MtrAMaxCpbltyTrqRcvd_write_IRV: category=VALUE, type=Boolean, init-value=0
          VeMTIR_Cnt_MtrAMaxCpbltyIndx_Init_IRV: category=VALUE, type=UInt8, init-value=0
          VaMTIR_M_MtrAMinCpbltyTrq_Poke_Init_IRV: category=ARRAY, type=rt_Array_Float_16, init-value=16 x 0
          VeMTIR_b_MtrAMinCpbltyTrqRcvd_write_IRV: category=VALUE, type=Boolean, init-value=0
          VaMTIR_n_MtrACpbltySpd_Poke_Init_IRV: category=ARRAY, type=rt_Array_Float_16, init-value=16 x 0
          VeMTIR_b_MtrACpbltySpdRcvd_write_IRV: category=VALUE, type=Boolean, init-value=0
          VeMTIR_b_MtrADrtngFctrRcvd_write_IRV: category=VALUE, type=Boolean, init-value=0
          VeMTIR_k_MtrADrtngFctr_Poke_Init_IRV: category=VALUE, type=Float, init-value=0
          VeMTIR_M_MtrB_TorqAchieved_write_IRV: category=VALUE, type=Float, init-value=0
          VeMTIR_b_MtrB_TorqAchievedFA_write_IRV: category=VALUE, type=Boolean, init-value=0
          VeMTIR_M_MtrB_MaxTorq_write_IRV: category=VALUE, type=Float, init-value=0
          VeMTIR_b_MtrB_MaxTorqSgnl_Rcvd_write_IRV: category=VALUE, type=Boolean, init-value=0
          VeMTIR_M_MtrB_MinTorq_write_IRV: category=VALUE, type=Float, init-value=0
          VeMTIR_b_MtrB_MinTorqSgnl_Rcvd_write_IRV: category=VALUE, type=Boolean, init-value=0
          VeMTIR_M_MtrB_TorqAchieved_AEMD_write_IRV: category=VALUE, type=Float, init-value=0
          VeMTIR_b_MtrB_TorqAchieved_AEMDFA_write_IRV: category=VALUE, type=Boolean, init-value=0
          VeMTIR_M_MtrBMaxTrqLmt_TCM_write_IRV: category=VALUE, type=Float, init-value=0
          VeMTIR_M_MtrBMinTrqLmt_TCM_write_IRV: category=VALUE, type=Float, init-value=0
          VaMTIR_M_MtrBMaxCpbltyTrq_Poke_Init_IRV: category=ARRAY, type=rt_Array_Float_16, init-value=16 x 0
          VeMTIR_b_MtrBMaxCpbltyTrqRcvd_write_IRV: category=VALUE, type=Boolean, init-value=0
          VeMTIR_Cnt_MtrBMaxCpbltyIndx_Init_IRV: category=VALUE, type=UInt8, init-value=0
          VaMTIR_M_MtrBMinCpbltyTrq_Poke_Init_IRV: category=ARRAY, type=rt_Array_Float_16, init-value=16 x 0
          VeMTIR_b_MtrBMinCpbltyRcvd_write_IRV: category=VALUE, type=Boolean, init-value=0
          VaMTIR_n_MtrBCpbltySpd_Poke_Init_IRV: category=ARRAY, type=rt_Array_Float_16, init-value=16 x 0
          VeMTIR_b_MtrBCpbltySpdRcvd_write_IRV: category=VALUE, type=Boolean, init-value=0
          VeMTIR_k_MtrBDrtngFctr_Init_IRV: category=VALUE, type=Float, init-value=0
          VeMTIR_b_MtrBDrtngFctrRcvd_write_IRV: category=VALUE, type=Boolean, init-value=0
          VeMTIR_M_MtrC_TorqAchieved_write_IRV: category=VALUE, type=Float, init-value=0
          VeMTIR_b_MtrC_TorqAchievedFA_write_IRV: category=VALUE, type=Boolean, init-value=0
          VeMTIR_M_MtrC_MaxTorq_write_IRV: category=VALUE, type=Float, init-value=0
          VeMTIR_M_MtrC_MinTorq_write_IRV: category=VALUE, type=Float, init-value=0
          VeMTIR_M_MtrC_TorqAchieved_AEMD_write_IRV: category=VALUE, type=Float, init-value=0
          VeMTIR_b_MtrC_TorqAchieved_AEMDFA_write_IRV: category=VALUE, type=Boolean, init-value=0
          VaMTIR_M_MtrCMaxCpbltyTrq_Poke_Init_IRV: category=ARRAY, type=rt_Array_Float_16, init-value=16 x 0
          VeMTIR_b_MtrCMaxCpbltyTrqRcvd_write_IRV: category=VALUE, type=Boolean, init-value=0
          VeMTIR_Cnt_MtrCMaxCpbltyIndx_Init_IRV: category=VALUE, type=UInt8, init-value=0
          VaMTIR_M_MtrCMinCpbltyTrq_Poke_Init_IRV: category=ARRAY, type=rt_Array_Float_16, init-value=16 x 0
          VeMTIR_b_MtrCMinCpbltyRcvd_write_IRV: category=VALUE, type=Boolean, init-value=0
          VaMTIR_n_MtrCCpbltySpd_Poke_Init_IRV: category=ARRAY, type=rt_Array_Float_16, init-value=16 x 0
          VeMTIR_b_MtrCCpbltySpdRcvd_write_IRV: category=VALUE, type=Boolean, init-value=0
          VeMTIR_k_MtrCDrtngFctr_Init_IRV: category=VALUE, type=Float, init-value=0
          VeMTIR_b_MtrCDrtngFctrRcvd_write_IRV: category=VALUE, type=Boolean, init-value=0
          VeMTIR_M_P2SpdCntrlMaxTrqLmt_Init_IRV: category=VALUE, type=Float, init-value=0
          VeMTIR_M_P2SpdCntrlMinTrqLmt_Init_IRV: category=VALUE, type=Float, init-value=0
          VeMTIR_b_MtrA_TorqAchievedSgnl_Rcvd_write_IRV: category=VALUE, type=Boolean, init-value=0
          VeMTIR_b_MtrA_TorqAchieved_AEMDSgnl_Rcvd_write_IRV: category=VALUE, type=Boolean, init-value=0
          VeMTIR_b_MtrB_TorqAchievedSgnl_Rcvd_write_IRV: category=VALUE, type=Boolean, init-value=0
          VeMTIR_b_MtrB_TorqAchieved_AEMDSgnl_Rcvd_write_IRV: category=VALUE, type=Boolean, init-value=0
          VeMTIR_b_MtrC_TorqAchievedSgnl_Rcvd_write_IRV: category=VALUE, type=Boolean, init-value=0
          VeMTIR_b_MtrC_TorqAchieved_AEMDSgnl_Rcvd_write_IRV: category=VALUE, type=Boolean, init-value=0
      83 x runnable:
        MTIR_ac_Init
          data-send-points:
            9 x access:
              OUT_VaMTIR_M_MtrAMaxCpblty_Value: accessed-variable=VaMTIR_M_MtrAMaxCpblty.Value
              OUT_VaMTIR_M_MtrAMinCpblty_Value: accessed-variable=VaMTIR_M_MtrAMinCpblty.Value
              OUT_VaMTIR_n_MtrACpbltySpd_Value: accessed-variable=VaMTIR_n_MtrACpbltySpd.Value
              OUT_VaMTIR_M_MtrBMaxCpblty_Value: accessed-variable=VaMTIR_M_MtrBMaxCpblty.Value
              OUT_VaMTIR_M_MtrBMinCpblty_Value: accessed-variable=VaMTIR_M_MtrBMinCpblty.Value
              OUT_VaMTIR_n_MtrBCpbltySpd_Value: accessed-variable=VaMTIR_n_MtrBCpbltySpd.Value
              OUT_VaMTIR_M_MtrCMaxCpblty_Value: accessed-variable=VaMTIR_M_MtrCMaxCpblty.Value
              OUT_VaMTIR_M_MtrCMinCpblty_Value: accessed-variable=VaMTIR_M_MtrCMinCpblty.Value
              OUT_VaMTIR_n_MtrCCpbltySpd_Value: accessed-variable=VaMTIR_n_MtrCCpbltySpd.Value
        MTIR_PwrOn
          data-send-points:
            35 x access:
              OUT_VeMTIR_M_MtrBMaxTrqLmt_TCMFA_Value: accessed-variable=VeMTIR_M_MtrBMaxTrqLmt_TCMFA.Value
              OUT_VeMTIR_M_MtrBMaxTrqLmt_TCM_Value: accessed-variable=VeMTIR_M_MtrBMaxTrqLmt_TCM.Value
              OUT_VeMTIR_M_MtrBMinTrqLmt_TCMFA_Value: accessed-variable=VeMTIR_M_MtrBMinTrqLmt_TCMFA.Value
              OUT_VeMTIR_M_MtrBMinTrqLmt_TCM_Value: accessed-variable=VeMTIR_M_MtrBMinTrqLmt_TCM.Value
              OUT_VaMTIR_M_MtrAMaxCpblty_Value: accessed-variable=VaMTIR_M_MtrAMaxCpblty.Value
              OUT_VaMTIR_M_MtrBMaxCpblty_Value: accessed-variable=VaMTIR_M_MtrBMaxCpblty.Value
              OUT_VaMTIR_M_MtrBMinCpblty_Value: accessed-variable=VaMTIR_M_MtrBMinCpblty.Value
              OUT_VaMTIR_n_MtrBCpbltySpd_Value: accessed-variable=VaMTIR_n_MtrBCpbltySpd.Value
              OUT_VaMTIR_M_MtrAMinCpblty_Value: accessed-variable=VaMTIR_M_MtrAMinCpblty.Value
              OUT_VaMTIR_n_MtrACpbltySpd_Value: accessed-variable=VaMTIR_n_MtrACpbltySpd.Value
              OUT_VaMTIR_M_MtrCMaxCpblty_Value: accessed-variable=VaMTIR_M_MtrCMaxCpblty.Value
              OUT_VaMTIR_M_MtrCMinCpblty_Value: accessed-variable=VaMTIR_M_MtrCMinCpblty.Value
              OUT_VaMTIR_n_MtrCCpbltySpd_Value: accessed-variable=VaMTIR_n_MtrCCpbltySpd.Value
              OUT_VeMTIR_M_MtrA_TorqAchieved_Value: accessed-variable=VeMTIR_M_MtrA_TorqAchieved.Value
              OUT_VeMTIR_b_MtrA_TorqAchievedFA_Value: accessed-variable=VeMTIR_b_MtrA_TorqAchievedFA.Value
              OUT_VeMTIR_M_MtrA_MaxTorqRaw_Value: accessed-variable=VeMTIR_M_MtrA_MaxTorqRaw.Value
              OUT_VeMTIR_M_MtrA_MinTorqRaw_Value: accessed-variable=VeMTIR_M_MtrA_MinTorqRaw.Value
              OUT_VeMTIR_M_MtrA_TorqAchieved_AEMD_Value: accessed-variable=VeMTIR_M_MtrA_TorqAchieved_AEMD.Value
              OUT_VeMTIR_M_MtrB_TorqAchieved_Value: accessed-variable=VeMTIR_M_MtrB_TorqAchieved.Value
              OUT_VeMTIR_b_MtrB_TorqAchievedFA_Value: accessed-variable=VeMTIR_b_MtrB_TorqAchievedFA.Value
              OUT_VeMTIR_M_MtrB_MaxTorqRaw_Value: accessed-variable=VeMTIR_M_MtrB_MaxTorqRaw.Value
              OUT_VeMTIR_M_MtrB_MinTorqRaw_Value: accessed-variable=VeMTIR_M_MtrB_MinTorqRaw.Value
              OUT_VeMTIR_M_MtrB_TorqAchieved_AEMD_Value: accessed-variable=VeMTIR_M_MtrB_TorqAchieved_AEMD.Value
              OUT_VeMTIR_M_P2SpdCntrlMaxTrqLmt_Value: accessed-variable=VeMTIR_M_P2SpdCntrlMaxTrqLmt.Value
              OUT_VeMTIR_M_P2SpdCntrlMinTrqLmt_Value: accessed-variable=VeMTIR_M_P2SpdCntrlMinTrqLmt.Value
              OUT_VeMTIR_M_MtrB_TorqAchievedCnvrtd_Value: accessed-variable=VeMTIR_M_MtrB_TorqAchievedCnvrtd.Value
              OUT_VeMTIR_b_InrtaCompAllwd_Value: accessed-variable=VeMTIR_b_InrtaCompAllwd.Value
              OUT_VeMTIR_k_MtrADrtngFctr_Value: accessed-variable=VeMTIR_k_MtrADrtngFctr.Value
              OUT_VeMTIR_k_MtrBDrtngFctr_Value: accessed-variable=VeMTIR_k_MtrBDrtngFctr.Value
              OUT_VeMTIR_M_MtrC_TorqAchieved_Value: accessed-variable=VeMTIR_M_MtrC_TorqAchieved.Value
              OUT_VeMTIR_b_MtrC_TorqAchievedFA_Value: accessed-variable=VeMTIR_b_MtrC_TorqAchievedFA.Value
              OUT_VeMTIR_M_MtrC_MaxTorqRaw_Value: accessed-variable=VeMTIR_M_MtrC_MaxTorqRaw.Value
              OUT_VeMTIR_M_MtrC_MinTorqRaw_Value: accessed-variable=VeMTIR_M_MtrC_MinTorqRaw.Value
              OUT_VeMTIR_M_MtrC_TorqAchieved_AEMD_Value: accessed-variable=VeMTIR_M_MtrC_TorqAchieved_AEMD.Value
              OUT_VeMTIR_k_MtrCDrtngFctr_Value: accessed-variable=VeMTIR_k_MtrCDrtngFctr.Value
          12 x parameter access:
            CALPRM_KtHSCR_M_Motor_Torque_Max_MtrA_KtHSCR_M_Motor_Torque_Max_MtrA: accessed-parameter=KtHSCR_M_Motor_Torque_Max_MtrA.KtHSCR_M_Motor_Torque_Max_MtrA
            CALPRM_KtHSCR_M_Motor_Torque_Max_MtrB_KtHSCR_M_Motor_Torque_Max_MtrB: accessed-parameter=KtHSCR_M_Motor_Torque_Max_MtrB.KtHSCR_M_Motor_Torque_Max_MtrB
            CALPRM_KtHSCR_M_Motor_Torque_Max_MtrC_KtHSCR_M_Motor_Torque_Max_MtrC: accessed-parameter=KtHSCR_M_Motor_Torque_Max_MtrC.KtHSCR_M_Motor_Torque_Max_MtrC
            CALPRM_KtHSCR_M_Motor_Torque_Min_MtrA_KtHSCR_M_Motor_Torque_Min_MtrA: accessed-parameter=KtHSCR_M_Motor_Torque_Min_MtrA.KtHSCR_M_Motor_Torque_Min_MtrA
            CALPRM_KtHSCR_M_Motor_Torque_Min_MtrB_KtHSCR_M_Motor_Torque_Min_MtrB: accessed-parameter=KtHSCR_M_Motor_Torque_Min_MtrB.KtHSCR_M_Motor_Torque_Min_MtrB
            CALPRM_KtHSCR_M_Motor_Torque_Min_MtrC_KtHSCR_M_Motor_Torque_Min_MtrC: accessed-parameter=KtHSCR_M_Motor_Torque_Min_MtrC.KtHSCR_M_Motor_Torque_Min_MtrC
            CALPRM_KxHSCR_M_Motor_Torque_Max_MtrA_KxHSCR_M_Motor_Torque_Max_MtrA: accessed-parameter=KxHSCR_M_Motor_Torque_Max_MtrA.KxHSCR_M_Motor_Torque_Max_MtrA
            CALPRM_KxHSCR_M_Motor_Torque_Max_MtrB_KxHSCR_M_Motor_Torque_Max_MtrB: accessed-parameter=KxHSCR_M_Motor_Torque_Max_MtrB.KxHSCR_M_Motor_Torque_Max_MtrB
            CALPRM_KxHSCR_M_Motor_Torque_Max_MtrC_KxHSCR_M_Motor_Torque_Max_MtrC: accessed-parameter=KxHSCR_M_Motor_Torque_Max_MtrC.KxHSCR_M_Motor_Torque_Max_MtrC
            CALPRM_KxHSCR_M_Motor_Torque_Min_MtrA_KxHSCR_M_Motor_Torque_Min_MtrA: accessed-parameter=KxHSCR_M_Motor_Torque_Min_MtrA.KxHSCR_M_Motor_Torque_Min_MtrA
            CALPRM_KxHSCR_M_Motor_Torque_Min_MtrB_KxHSCR_M_Motor_Torque_Min_MtrB: accessed-parameter=KxHSCR_M_Motor_Torque_Min_MtrB.KxHSCR_M_Motor_Torque_Min_MtrB
            CALPRM_KxHSCR_M_Motor_Torque_Min_MtrC_KxHSCR_M_Motor_Torque_Min_MtrC: accessed-parameter=KxHSCR_M_Motor_Torque_Min_MtrC.KxHSCR_M_Motor_Torque_Min_MtrC
          written-local-variables:
            49 x access:
              WV_VaMTIR_M_MtrAMaxCpbltyTrq_Poke_Init_IRV: accessed-variable=VaMTIR_M_MtrAMaxCpbltyTrq_Poke_Init_IRV
              WV_VaMTIR_M_MtrAMinCpbltyTrq_Poke_Init_IRV: accessed-variable=VaMTIR_M_MtrAMinCpbltyTrq_Poke_Init_IRV
              WV_VaMTIR_M_MtrBMaxCpbltyTrq_Poke_Init_IRV: accessed-variable=VaMTIR_M_MtrBMaxCpbltyTrq_Poke_Init_IRV
              WV_VaMTIR_M_MtrBMinCpbltyTrq_Poke_Init_IRV: accessed-variable=VaMTIR_M_MtrBMinCpbltyTrq_Poke_Init_IRV
              WV_VaMTIR_M_MtrCMaxCpbltyTrq_Poke_Init_IRV: accessed-variable=VaMTIR_M_MtrCMaxCpbltyTrq_Poke_Init_IRV
              WV_VaMTIR_M_MtrCMinCpbltyTrq_Poke_Init_IRV: accessed-variable=VaMTIR_M_MtrCMinCpbltyTrq_Poke_Init_IRV
              WV_VaMTIR_n_MtrACpbltySpd_Poke_Init_IRV: accessed-variable=VaMTIR_n_MtrACpbltySpd_Poke_Init_IRV
              WV_VaMTIR_n_MtrBCpbltySpd_Poke_Init_IRV: accessed-variable=VaMTIR_n_MtrBCpbltySpd_Poke_Init_IRV
              WV_VaMTIR_n_MtrCCpbltySpd_Poke_Init_IRV: accessed-variable=VaMTIR_n_MtrCCpbltySpd_Poke_Init_IRV
              WV_VeMTIR_Cnt_MtrAMaxCpbltyIndx_Init_IRV: accessed-variable=VeMTIR_Cnt_MtrAMaxCpbltyIndx_Init_IRV
              WV_VeMTIR_Cnt_MtrBMaxCpbltyIndx_Init_IRV: accessed-variable=VeMTIR_Cnt_MtrBMaxCpbltyIndx_Init_IRV
              WV_VeMTIR_Cnt_MtrCMaxCpbltyIndx_Init_IRV: accessed-variable=VeMTIR_Cnt_MtrCMaxCpbltyIndx_Init_IRV
              WV_VeMTIR_M_MtrA_MaxTorq_write_IRV: accessed-variable=VeMTIR_M_MtrA_MaxTorq_write_IRV
              WV_VeMTIR_M_MtrA_MinTorq_write_IRV: accessed-variable=VeMTIR_M_MtrA_MinTorq_write_IRV
              WV_VeMTIR_M_MtrA_TorqAchieved_AEMD_write_IRV: accessed-variable=VeMTIR_M_MtrA_TorqAchieved_AEMD_write_IRV
              WV_VeMTIR_M_MtrA_TorqAchieved_write_IRV: accessed-variable=VeMTIR_M_MtrA_TorqAchieved_write_IRV
              WV_VeMTIR_b_MtrBMaxCpbltyTrqRcvd_write_IRV: accessed-variable=VeMTIR_b_MtrBMaxCpbltyTrqRcvd_write_IRV
              WV_VeMTIR_b_MtrBMinCpbltyRcvd_write_IRV: accessed-variable=VeMTIR_b_MtrBMinCpbltyRcvd_write_IRV
              WV_VeMTIR_M_MtrBMaxTrqLmt_TCM_write_IRV: accessed-variable=VeMTIR_M_MtrBMaxTrqLmt_TCM_write_IRV
              WV_VeMTIR_M_MtrBMinTrqLmt_TCM_write_IRV: accessed-variable=VeMTIR_M_MtrBMinTrqLmt_TCM_write_IRV
              WV_VeMTIR_M_MtrB_MaxTorq_write_IRV: accessed-variable=VeMTIR_M_MtrB_MaxTorq_write_IRV
              WV_VeMTIR_M_MtrB_MinTorq_write_IRV: accessed-variable=VeMTIR_M_MtrB_MinTorq_write_IRV
              WV_VeMTIR_M_MtrB_TorqAchieved_AEMD_write_IRV: accessed-variable=VeMTIR_M_MtrB_TorqAchieved_AEMD_write_IRV
              WV_VeMTIR_M_MtrB_TorqAchieved_write_IRV: accessed-variable=VeMTIR_M_MtrB_TorqAchieved_write_IRV
              WV_VeMTIR_b_MtrCMaxCpbltyTrqRcvd_write_IRV: accessed-variable=VeMTIR_b_MtrCMaxCpbltyTrqRcvd_write_IRV
              WV_VeMTIR_b_MtrCMinCpbltyRcvd_write_IRV: accessed-variable=VeMTIR_b_MtrCMinCpbltyRcvd_write_IRV
              WV_VeMTIR_M_MtrC_MaxTorq_write_IRV: accessed-variable=VeMTIR_M_MtrC_MaxTorq_write_IRV
              WV_VeMTIR_M_MtrC_MinTorq_write_IRV: accessed-variable=VeMTIR_M_MtrC_MinTorq_write_IRV
              WV_VeMTIR_M_MtrC_TorqAchieved_AEMD_write_IRV: accessed-variable=VeMTIR_M_MtrC_TorqAchieved_AEMD_write_IRV
              WV_VeMTIR_M_MtrC_TorqAchieved_write_IRV: accessed-variable=VeMTIR_M_MtrC_TorqAchieved_write_IRV
              WV_VeMTIR_M_P2SpdCntrlMaxTrqLmt_Init_IRV: accessed-variable=VeMTIR_M_P2SpdCntrlMaxTrqLmt_Init_IRV
              WV_VeMTIR_M_P2SpdCntrlMinTrqLmt_Init_IRV: accessed-variable=VeMTIR_M_P2SpdCntrlMinTrqLmt_Init_IRV
              WV_VeMTIR_b_MtrAMinCpbltyTrqRcvd_write_IRV: accessed-variable=VeMTIR_b_MtrAMinCpbltyTrqRcvd_write_IRV
              WV_VeMTIR_b_MtrACpbltySpdRcvd_write_IRV: accessed-variable=VeMTIR_b_MtrACpbltySpdRcvd_write_IRV
              WV_VeMTIR_b_MtrADrtngFctrRcvd_write_IRV: accessed-variable=VeMTIR_b_MtrADrtngFctrRcvd_write_IRV
              WV_VeMTIR_b_MtrAMaxCpbltyTrqRcvd_write_IRV: accessed-variable=VeMTIR_b_MtrAMaxCpbltyTrqRcvd_write_IRV
              WV_VeMTIR_b_MtrA_TorqAchievedFA_write_IRV: accessed-variable=VeMTIR_b_MtrA_TorqAchievedFA_write_IRV
              WV_VeMTIR_b_MtrA_TorqAchieved_AEMDFA_write_IRV: accessed-variable=VeMTIR_b_MtrA_TorqAchieved_AEMDFA_write_IRV
              WV_VeMTIR_b_MtrB_TorqAchievedFA_write_IRV: accessed-variable=VeMTIR_b_MtrB_TorqAchievedFA_write_IRV
              WV_VeMTIR_b_MtrB_TorqAchieved_AEMDFA_write_IRV: accessed-variable=VeMTIR_b_MtrB_TorqAchieved_AEMDFA_write_IRV
              WV_VeMTIR_b_MtrCCpbltySpdRcvd_write_IRV: accessed-variable=VeMTIR_b_MtrCCpbltySpdRcvd_write_IRV
              WV_VeMTIR_b_MtrC_TorqAchievedFA_write_IRV: accessed-variable=VeMTIR_b_MtrC_TorqAchievedFA_write_IRV
              WV_VeMTIR_b_MtrC_TorqAchieved_AEMDFA_write_IRV: accessed-variable=VeMTIR_b_MtrC_TorqAchieved_AEMDFA_write_IRV
              WV_VeMTIR_k_MtrADrtngFctr_Poke_Init_IRV: accessed-variable=VeMTIR_k_MtrADrtngFctr_Poke_Init_IRV
              WV_VeMTIR_b_MtrBDrtngFctrRcvd_write_IRV: accessed-variable=VeMTIR_b_MtrBDrtngFctrRcvd_write_IRV
              WV_VeMTIR_k_MtrBDrtngFctr_Init_IRV: accessed-variable=VeMTIR_k_MtrBDrtngFctr_Init_IRV
              WV_VeMTIR_b_MtrCDrtngFctrRcvd_write_IRV: accessed-variable=VeMTIR_b_MtrCDrtngFctrRcvd_write_IRV
              WV_VeMTIR_k_MtrCDrtngFctr_Init_IRV: accessed-variable=VeMTIR_k_MtrCDrtngFctr_Init_IRV
              WV_VeMTIR_b_MtrBCpbltySpdRcvd_write_IRV: accessed-variable=VeMTIR_b_MtrBCpbltySpdRcvd_write_IRV
        MTIR_FastTEF
          data-receive-point-by-arguments:
            access IN_VeHVTR_U_HV_Volt_Value: accessed-variable=VeHVTR_U_HV_Volt.Value
          data-send-points:
            31 x access:
              OUT_VaMTIR_M_MtrAMaxCpblty_Value: accessed-variable=VaMTIR_M_MtrAMaxCpblty.Value
              OUT_VaMTIR_M_MtrBMaxCpblty_Value: accessed-variable=VaMTIR_M_MtrBMaxCpblty.Value
              OUT_VaMTIR_M_MtrBMinCpblty_Value: accessed-variable=VaMTIR_M_MtrBMinCpblty.Value
              OUT_VaMTIR_n_MtrBCpbltySpd_Value: accessed-variable=VaMTIR_n_MtrBCpbltySpd.Value
              OUT_VaMTIR_M_MtrAMinCpblty_Value: accessed-variable=VaMTIR_M_MtrAMinCpblty.Value
              OUT_VaMTIR_n_MtrACpbltySpd_Value: accessed-variable=VaMTIR_n_MtrACpbltySpd.Value
              OUT_VaMTIR_M_MtrCMaxCpblty_Value: accessed-variable=VaMTIR_M_MtrCMaxCpblty.Value
              OUT_VaMTIR_M_MtrCMinCpblty_Value: accessed-variable=VaMTIR_M_MtrCMinCpblty.Value
              OUT_VaMTIR_n_MtrCCpbltySpd_Value: accessed-variable=VaMTIR_n_MtrCCpbltySpd.Value
              OUT_VeMTIR_b_MtrA_TorqAchievedFA_Value: accessed-variable=VeMTIR_b_MtrA_TorqAchievedFA.Value
              OUT_VeMTIR_M_MtrA_MaxTorqRaw_Value: accessed-variable=VeMTIR_M_MtrA_MaxTorqRaw.Value
              OUT_VeMTIR_M_MtrA_MinTorqRaw_Value: accessed-variable=VeMTIR_M_MtrA_MinTorqRaw.Value
              OUT_VeMTIR_b_MtrB_TorqAchievedFA_Value: accessed-variable=VeMTIR_b_MtrB_TorqAchievedFA.Value
              OUT_VeMTIR_M_MtrB_MaxTorqRaw_Value: accessed-variable=VeMTIR_M_MtrB_MaxTorqRaw.Value
              OUT_VeMTIR_M_MtrB_MinTorqRaw_Value: accessed-variable=VeMTIR_M_MtrB_MinTorqRaw.Value
              OUT_VeMTIR_M_P2SpdCntrlMaxTrqLmt_Value: accessed-variable=VeMTIR_M_P2SpdCntrlMaxTrqLmt.Value
              OUT_VeMTIR_M_P2SpdCntrlMinTrqLmt_Value: accessed-variable=VeMTIR_M_P2SpdCntrlMinTrqLmt.Value
              OUT_VeMTIR_b_InrtaCompAllwd_Value: accessed-variable=VeMTIR_b_InrtaCompAllwd.Value
              OUT_VeMTIR_k_MtrADrtngFctr_Value: accessed-variable=VeMTIR_k_MtrADrtngFctr.Value
              OUT_VeMTIR_k_MtrBDrtngFctr_Value: accessed-variable=VeMTIR_k_MtrBDrtngFctr.Value
              OUT_VeMTIR_b_MtrC_TorqAchievedFA_Value: accessed-variable=VeMTIR_b_MtrC_TorqAchievedFA.Value
              OUT_VeMTIR_M_MtrC_MaxTorqRaw_Value: accessed-variable=VeMTIR_M_MtrC_MaxTorqRaw.Value
              OUT_VeMTIR_M_MtrC_MinTorqRaw_Value: accessed-variable=VeMTIR_M_MtrC_MinTorqRaw.Value
              OUT_VeMTIR_k_MtrCDrtngFctr_Value: accessed-variable=VeMTIR_k_MtrCDrtngFctr.Value
              OUT_VeMTIR_M_MtrA_TorqAchieved_Value: accessed-variable=VeMTIR_M_MtrA_TorqAchieved.Value
              OUT_VeMTIR_M_MtrA_TorqAchieved_AEMD_Value: accessed-variable=VeMTIR_M_MtrA_TorqAchieved_AEMD.Value
              OUT_VeMTIR_M_MtrB_TorqAchieved_Value: accessed-variable=VeMTIR_M_MtrB_TorqAchieved.Value
              OUT_VeMTIR_M_MtrB_TorqAchieved_AEMD_Value: accessed-variable=VeMTIR_M_MtrB_TorqAchieved_AEMD.Value
              OUT_VeMTIR_M_MtrB_TorqAchievedCnvrtd_Value: accessed-variable=VeMTIR_M_MtrB_TorqAchievedCnvrtd.Value
              OUT_VeMTIR_M_MtrC_TorqAchieved_Value: accessed-variable=VeMTIR_M_MtrC_TorqAchieved.Value
              OUT_VeMTIR_M_MtrC_TorqAchieved_AEMD_Value: accessed-variable=VeMTIR_M_MtrC_TorqAchieved_AEMD.Value
          read-local-variables:
            44 x access:
              RV_VaMTIR_M_MtrAMaxCpbltyTrq_Poke_Init_IRV: accessed-variable=VaMTIR_M_MtrAMaxCpbltyTrq_Poke_Init_IRV
              RV_VaMTIR_M_MtrAMinCpbltyTrq_Poke_Init_IRV: accessed-variable=VaMTIR_M_MtrAMinCpbltyTrq_Poke_Init_IRV
              RV_VaMTIR_M_MtrBMaxCpbltyTrq_Poke_Init_IRV: accessed-variable=VaMTIR_M_MtrBMaxCpbltyTrq_Poke_Init_IRV
              RV_VaMTIR_M_MtrBMinCpbltyTrq_Poke_Init_IRV: accessed-variable=VaMTIR_M_MtrBMinCpbltyTrq_Poke_Init_IRV
              RV_VaMTIR_n_MtrACpbltySpd_Poke_Init_IRV: accessed-variable=VaMTIR_n_MtrACpbltySpd_Poke_Init_IRV
              RV_VaMTIR_n_MtrBCpbltySpd_Poke_Init_IRV: accessed-variable=VaMTIR_n_MtrBCpbltySpd_Poke_Init_IRV
              RV_VeMTIR_Cnt_MtrAMaxCpbltyIndx_Init_IRV: accessed-variable=VeMTIR_Cnt_MtrAMaxCpbltyIndx_Init_IRV
              RV_VeMTIR_Cnt_MtrBMaxCpbltyIndx_Init_IRV: accessed-variable=VeMTIR_Cnt_MtrBMaxCpbltyIndx_Init_IRV
              RV_VeMTIR_M_MtrA_MaxTorq_write_IRV: accessed-variable=VeMTIR_M_MtrA_MaxTorq_write_IRV
              RV_VeMTIR_M_MtrA_MinTorq_write_IRV: accessed-variable=VeMTIR_M_MtrA_MinTorq_write_IRV
              RV_VeMTIR_M_MtrA_TorqAchieved_AEMD_write_IRV: accessed-variable=VeMTIR_M_MtrA_TorqAchieved_AEMD_write_IRV
              RV_VeMTIR_M_MtrA_TorqAchieved_write_IRV: accessed-variable=VeMTIR_M_MtrA_TorqAchieved_write_IRV
              RV_VeMTIR_M_MtrBMaxTrqLmt_TCM_write_IRV: accessed-variable=VeMTIR_M_MtrBMaxTrqLmt_TCM_write_IRV
              RV_VeMTIR_M_MtrBMinTrqLmt_TCM_write_IRV: accessed-variable=VeMTIR_M_MtrBMinTrqLmt_TCM_write_IRV
              RV_VeMTIR_M_MtrB_MaxTorq_write_IRV: accessed-variable=VeMTIR_M_MtrB_MaxTorq_write_IRV
              RV_VeMTIR_M_MtrB_MinTorq_write_IRV: accessed-variable=VeMTIR_M_MtrB_MinTorq_write_IRV
              RV_VeMTIR_M_MtrB_TorqAchieved_AEMD_write_IRV: accessed-variable=VeMTIR_M_MtrB_TorqAchieved_AEMD_write_IRV
              RV_VeMTIR_M_MtrB_TorqAchieved_write_IRV: accessed-variable=VeMTIR_M_MtrB_TorqAchieved_write_IRV
              RV_VeMTIR_M_P2SpdCntrlMaxTrqLmt_Init_IRV: accessed-variable=VeMTIR_M_P2SpdCntrlMaxTrqLmt_Init_IRV
              RV_VeMTIR_M_P2SpdCntrlMinTrqLmt_Init_IRV: accessed-variable=VeMTIR_M_P2SpdCntrlMinTrqLmt_Init_IRV
              RV_VeMTIR_b_MtrACpbltySpdRcvd_write_IRV: accessed-variable=VeMTIR_b_MtrACpbltySpdRcvd_write_IRV
              RV_VeMTIR_b_MtrADrtngFctrRcvd_write_IRV: accessed-variable=VeMTIR_b_MtrADrtngFctrRcvd_write_IRV
              RV_VeMTIR_b_MtrAMaxCpbltyTrqRcvd_write_IRV: accessed-variable=VeMTIR_b_MtrAMaxCpbltyTrqRcvd_write_IRV
              RV_VeMTIR_b_MtrAMinCpbltyTrqRcvd_write_IRV: accessed-variable=VeMTIR_b_MtrAMinCpbltyTrqRcvd_write_IRV
              RV_VeMTIR_b_MtrA_MaxTorqSgnl_Rcvd_write_IRV: accessed-variable=VeMTIR_b_MtrA_MaxTorqSgnl_Rcvd_write_IRV
              RV_VeMTIR_b_MtrA_MinTorqSgnl_Rcvd_write_IRV: accessed-variable=VeMTIR_b_MtrA_MinTorqSgnl_Rcvd_write_IRV
              RV_VeMTIR_b_MtrA_TorqAchievedFA_write_IRV: accessed-variable=VeMTIR_b_MtrA_TorqAchievedFA_write_IRV
              RV_VeMTIR_b_MtrA_TorqAchievedSgnl_Rcvd_write_IRV: accessed-variable=VeMTIR_b_MtrA_TorqAchievedSgnl_Rcvd_write_IRV
              RV_VeMTIR_b_MtrA_TorqAchieved_AEMDFA_write_IRV: accessed-variable=VeMTIR_b_MtrA_TorqAchieved_AEMDFA_write_IRV
              RV_VeMTIR_b_MtrA_TorqAchieved_AEMDSgnl_Rcvd_write_IRV: accessed-variable=VeMTIR_b_MtrA_TorqAchieved_AEMDSgnl_Rcvd_write_IRV
              RV_VeMTIR_b_MtrBCpbltySpdRcvd_write_IRV: accessed-variable=VeMTIR_b_MtrBCpbltySpdRcvd_write_IRV
              RV_VeMTIR_b_MtrBDrtngFctrRcvd_write_IRV: accessed-variable=VeMTIR_b_MtrBDrtngFctrRcvd_write_IRV
              RV_VeMTIR_b_MtrBMaxCpbltyTrqRcvd_write_IRV: accessed-variable=VeMTIR_b_MtrBMaxCpbltyTrqRcvd_write_IRV
              RV_VeMTIR_b_MtrBMinCpbltyRcvd_write_IRV: accessed-variable=VeMTIR_b_MtrBMinCpbltyRcvd_write_IRV
              RV_VeMTIR_b_MtrB_MaxTorqSgnl_Rcvd_write_IRV: accessed-variable=VeMTIR_b_MtrB_MaxTorqSgnl_Rcvd_write_IRV
              RV_VeMTIR_b_MtrB_MinTorqSgnl_Rcvd_write_IRV: accessed-variable=VeMTIR_b_MtrB_MinTorqSgnl_Rcvd_write_IRV
              RV_VeMTIR_b_MtrB_TorqAchievedFA_write_IRV: accessed-variable=VeMTIR_b_MtrB_TorqAchievedFA_write_IRV
              RV_VeMTIR_b_MtrB_TorqAchievedSgnl_Rcvd_write_IRV: accessed-variable=VeMTIR_b_MtrB_TorqAchievedSgnl_Rcvd_write_IRV
              RV_VeMTIR_b_MtrB_TorqAchieved_AEMDFA_write_IRV: accessed-variable=VeMTIR_b_MtrB_TorqAchieved_AEMDFA_write_IRV
              RV_VeMTIR_b_MtrB_TorqAchieved_AEMDSgnl_Rcvd_write_IRV: accessed-variable=VeMTIR_b_MtrB_TorqAchieved_AEMDSgnl_Rcvd_write_IRV
              RV_VeMTIR_b_MtrC_TorqAchievedSgnl_Rcvd_write_IRV: accessed-variable=VeMTIR_b_MtrC_TorqAchievedSgnl_Rcvd_write_IRV
              RV_VeMTIR_b_MtrC_TorqAchieved_AEMDSgnl_Rcvd_write_IRV: accessed-variable=VeMTIR_b_MtrC_TorqAchieved_AEMDSgnl_Rcvd_write_IRV
              RV_VeMTIR_k_MtrADrtngFctr_Poke_Init_IRV: accessed-variable=VeMTIR_k_MtrADrtngFctr_Poke_Init_IRV
              RV_VeMTIR_k_MtrBDrtngFctr_Init_IRV: accessed-variable=VeMTIR_k_MtrBDrtngFctr_Init_IRV
        FsftMTIR_M_MtrACapabilityMax
          written-local-variables:
            access WV_VeMTIR_b_MtrAMaxCpbltyTrqRcvd_write_IRV: accessed-variable=VeMTIR_b_MtrAMaxCpbltyTrqRcvd_write_IRV
        FsftMTIR_M_MtrACapabilityMin
          written-local-variables:
            access WV_VeMTIR_b_MtrAMinCpbltyTrqRcvd_write_IRV: accessed-variable=VeMTIR_b_MtrAMinCpbltyTrqRcvd_write_IRV
        FsftMTIR_M_MtrA_MaxTorq
          written-local-variables:
            access WV_VeMTIR_M_MtrA_MaxTorq_write_IRV: accessed-variable=VeMTIR_M_MtrA_MaxTorq_write_IRV
            access WV_VeMTIR_b_MtrA_MaxTorqSgnl_Rcvd_write_IRV: accessed-variable=VeMTIR_b_MtrA_MaxTorqSgnl_Rcvd_write_IRV
        FsftMTIR_M_MtrA_MinTorq
          written-local-variables:
            access WV_VeMTIR_M_MtrA_MinTorq_write_IRV: accessed-variable=VeMTIR_M_MtrA_MinTorq_write_IRV
            access WV_VeMTIR_b_MtrA_MinTorqSgnl_Rcvd_write_IRV: accessed-variable=VeMTIR_b_MtrA_MinTorqSgnl_Rcvd_write_IRV
        FsftMTIR_M_MtrA_TorqAchieved
          written-local-variables:
            access WV_VeMTIR_M_MtrA_TorqAchieved_write_IRV: accessed-variable=VeMTIR_M_MtrA_TorqAchieved_write_IRV
            access WV_VeMTIR_b_MtrA_TorqAchievedFA_write_IRV: accessed-variable=VeMTIR_b_MtrA_TorqAchievedFA_write_IRV
            access WV_VeMTIR_b_MtrA_TorqAchievedSgnl_Rcvd_write_IRV: accessed-variable=VeMTIR_b_MtrA_TorqAchievedSgnl_Rcvd_write_IRV
        FsftMTIR_M_MtrA_TorqAchieved_AEMD
          written-local-variables:
            access WV_VeMTIR_M_MtrA_TorqAchieved_AEMD_write_IRV: accessed-variable=VeMTIR_M_MtrA_TorqAchieved_AEMD_write_IRV
            access WV_VeMTIR_b_MtrA_TorqAchieved_AEMDFA_write_IRV: accessed-variable=VeMTIR_b_MtrA_TorqAchieved_AEMDFA_write_IRV
            access WV_VeMTIR_b_MtrA_TorqAchieved_AEMDSgnl_Rcvd_write_IRV: accessed-variable=VeMTIR_b_MtrA_TorqAchieved_AEMDSgnl_Rcvd_write_IRV
        FsftMTIR_M_MtrBCapabilityMax
          written-local-variables:
            access WV_VeMTIR_b_MtrBMaxCpbltyTrqRcvd_write_IRV: accessed-variable=VeMTIR_b_MtrBMaxCpbltyTrqRcvd_write_IRV
        FsftMTIR_M_MtrBCapabilityMin
          written-local-variables:
            access WV_VeMTIR_b_MtrBMinCpbltyRcvd_write_IRV: accessed-variable=VeMTIR_b_MtrBMinCpbltyRcvd_write_IRV
        FsftMTIR_M_MtrBMaxTrqLmt_TCM
          data-send-points:
            access OUT_VeMTIR_M_MtrBMaxTrqLmt_TCM_Value: accessed-variable=VeMTIR_M_MtrBMaxTrqLmt_TCM.Value
            access OUT_VeMTIR_M_MtrBMaxTrqLmt_TCMFA_Value: accessed-variable=VeMTIR_M_MtrBMaxTrqLmt_TCMFA.Value
          written-local-variables:
            access WV_VeMTIR_M_MtrBMaxTrqLmt_TCM_write_IRV: accessed-variable=VeMTIR_M_MtrBMaxTrqLmt_TCM_write_IRV
        FsftMTIR_M_MtrBMinTrqLmt_TCM
          data-send-points:
            access OUT_VeMTIR_M_MtrBMinTrqLmt_TCM_Value: accessed-variable=VeMTIR_M_MtrBMinTrqLmt_TCM.Value
            access OUT_VeMTIR_M_MtrBMinTrqLmt_TCMFA_Value: accessed-variable=VeMTIR_M_MtrBMinTrqLmt_TCMFA.Value
          written-local-variables:
            access WV_VeMTIR_M_MtrBMinTrqLmt_TCM_write_IRV: accessed-variable=VeMTIR_M_MtrBMinTrqLmt_TCM_write_IRV
        FsftMTIR_M_MtrB_MaxTorq
          written-local-variables:
            access WV_VeMTIR_M_MtrB_MaxTorq_write_IRV: accessed-variable=VeMTIR_M_MtrB_MaxTorq_write_IRV
            access WV_VeMTIR_b_MtrB_MaxTorqSgnl_Rcvd_write_IRV: accessed-variable=VeMTIR_b_MtrB_MaxTorqSgnl_Rcvd_write_IRV
        FsftMTIR_M_MtrB_MinTorq
          written-local-variables:
            access WV_VeMTIR_M_MtrB_MinTorq_write_IRV: accessed-variable=VeMTIR_M_MtrB_MinTorq_write_IRV
            access WV_VeMTIR_b_MtrB_MinTorqSgnl_Rcvd_write_IRV: accessed-variable=VeMTIR_b_MtrB_MinTorqSgnl_Rcvd_write_IRV
        FsftMTIR_M_MtrB_TorqAchieved
          written-local-variables:
            access WV_VeMTIR_M_MtrB_TorqAchieved_write_IRV: accessed-variable=VeMTIR_M_MtrB_TorqAchieved_write_IRV
            access WV_VeMTIR_b_MtrB_TorqAchievedFA_write_IRV: accessed-variable=VeMTIR_b_MtrB_TorqAchievedFA_write_IRV
            access WV_VeMTIR_b_MtrB_TorqAchievedSgnl_Rcvd_write_IRV: accessed-variable=VeMTIR_b_MtrB_TorqAchievedSgnl_Rcvd_write_IRV
        FsftMTIR_M_MtrB_TorqAchieved_AEMD
          written-local-variables:
            access WV_VeMTIR_M_MtrB_TorqAchieved_AEMD_write_IRV: accessed-variable=VeMTIR_M_MtrB_TorqAchieved_AEMD_write_IRV
            access WV_VeMTIR_b_MtrB_TorqAchieved_AEMDFA_write_IRV: accessed-variable=VeMTIR_b_MtrB_TorqAchieved_AEMDFA_write_IRV
            access WV_VeMTIR_b_MtrB_TorqAchieved_AEMDSgnl_Rcvd_write_IRV: accessed-variable=VeMTIR_b_MtrB_TorqAchieved_AEMDSgnl_Rcvd_write_IRV
        FsftMTIR_M_MtrCCapabilityMax
        FsftMTIR_M_MtrCCapabilityMin
        FsftMTIR_M_MtrC_MaxTorq
        FsftMTIR_M_MtrC_MinTorq
        FsftMTIR_M_MtrC_TorqAchieved
          written-local-variables:
            access WV_VeMTIR_b_MtrC_TorqAchievedSgnl_Rcvd_write_IRV: accessed-variable=VeMTIR_b_MtrC_TorqAchievedSgnl_Rcvd_write_IRV
        FsftMTIR_M_MtrC_TorqAchieved_AEMD
          written-local-variables:
            access WV_VeMTIR_b_MtrC_TorqAchieved_AEMDSgnl_Rcvd_write_IRV: accessed-variable=VeMTIR_b_MtrC_TorqAchieved_AEMDSgnl_Rcvd_write_IRV
        FsftMTIR_M_P2SpdCntrlMaxTrqLmt
        FsftMTIR_M_P2SpdCntrlMinTrqLmt
        FsftMTIR_k_MtrADeratingFactor
          written-local-variables:
            access WV_VeMTIR_b_MtrADrtngFctrRcvd_write_IRV: accessed-variable=VeMTIR_b_MtrADrtngFctrRcvd_write_IRV
        FsftMTIR_k_MtrBDeratingFactor
          written-local-variables:
            access WV_VeMTIR_b_MtrBDrtngFctrRcvd_write_IRV: accessed-variable=VeMTIR_b_MtrBDrtngFctrRcvd_write_IRV
        FsftMTIR_k_MtrCDeratingFactor
        FsftMTIR_n_MtrACapabilitySpd
          written-local-variables:
            access WV_VeMTIR_b_MtrACpbltySpdRcvd_write_IRV: accessed-variable=VeMTIR_b_MtrACpbltySpdRcvd_write_IRV
        FsftMTIR_n_MtrBCapabilitySpd
          written-local-variables:
            access WV_VeMTIR_b_MtrBCpbltySpdRcvd_write_IRV: accessed-variable=VeMTIR_b_MtrBCpbltySpdRcvd_write_IRV
        FsftMTIR_n_MtrCCapabilitySpd
        PokeMTIR_M_MtrACapabilityMax
          written-local-variables:
            access WV_VaMTIR_M_MtrAMaxCpbltyTrq_Poke_Init_IRV: accessed-variable=VaMTIR_M_MtrAMaxCpbltyTrq_Poke_Init_IRV
            access WV_VeMTIR_Cnt_MtrAMaxCpbltyIndx_Init_IRV: accessed-variable=VeMTIR_Cnt_MtrAMaxCpbltyIndx_Init_IRV
            access WV_VeMTIR_b_MtrAMaxCpbltyTrqRcvd_write_IRV: accessed-variable=VeMTIR_b_MtrAMaxCpbltyTrqRcvd_write_IRV
        PokeMTIR_M_MtrACapabilityMin
          written-local-variables:
            access WV_VaMTIR_M_MtrAMinCpbltyTrq_Poke_Init_IRV: accessed-variable=VaMTIR_M_MtrAMinCpbltyTrq_Poke_Init_IRV
            access WV_VeMTIR_b_MtrAMinCpbltyTrqRcvd_write_IRV: accessed-variable=VeMTIR_b_MtrAMinCpbltyTrqRcvd_write_IRV
        PokeMTIR_M_MtrA_MaxTorq
          written-local-variables:
            access WV_VeMTIR_M_MtrA_MaxTorq_write_IRV: accessed-variable=VeMTIR_M_MtrA_MaxTorq_write_IRV
            access WV_VeMTIR_b_MtrA_MaxTorqSgnl_Rcvd_write_IRV: accessed-variable=VeMTIR_b_MtrA_MaxTorqSgnl_Rcvd_write_IRV
        PokeMTIR_M_MtrA_MinTorq
          written-local-variables:
            access WV_VeMTIR_M_MtrA_MinTorq_write_IRV: accessed-variable=VeMTIR_M_MtrA_MinTorq_write_IRV
            access WV_VeMTIR_b_MtrA_MinTorqSgnl_Rcvd_write_IRV: accessed-variable=VeMTIR_b_MtrA_MinTorqSgnl_Rcvd_write_IRV
        PokeMTIR_M_MtrA_TorqAchieved
          written-local-variables:
            access WV_VeMTIR_M_MtrA_TorqAchieved_write_IRV: accessed-variable=VeMTIR_M_MtrA_TorqAchieved_write_IRV
            access WV_VeMTIR_b_MtrA_TorqAchievedFA_write_IRV: accessed-variable=VeMTIR_b_MtrA_TorqAchievedFA_write_IRV
            access WV_VeMTIR_b_MtrA_TorqAchievedSgnl_Rcvd_write_IRV: accessed-variable=VeMTIR_b_MtrA_TorqAchievedSgnl_Rcvd_write_IRV
        PokeMTIR_M_MtrA_TorqAchieved_AEMD
          written-local-variables:
            access WV_VeMTIR_M_MtrA_TorqAchieved_AEMD_write_IRV: accessed-variable=VeMTIR_M_MtrA_TorqAchieved_AEMD_write_IRV
            access WV_VeMTIR_b_MtrA_TorqAchieved_AEMDFA_write_IRV: accessed-variable=VeMTIR_b_MtrA_TorqAchieved_AEMDFA_write_IRV
            access WV_VeMTIR_b_MtrA_TorqAchieved_AEMDSgnl_Rcvd_write_IRV: accessed-variable=VeMTIR_b_MtrA_TorqAchieved_AEMDSgnl_Rcvd_write_IRV
        PokeMTIR_M_MtrBCapabilityMax
          written-local-variables:
            access WV_VaMTIR_M_MtrBMaxCpbltyTrq_Poke_Init_IRV: accessed-variable=VaMTIR_M_MtrBMaxCpbltyTrq_Poke_Init_IRV
            access WV_VeMTIR_Cnt_MtrBMaxCpbltyIndx_Init_IRV: accessed-variable=VeMTIR_Cnt_MtrBMaxCpbltyIndx_Init_IRV
            access WV_VeMTIR_b_MtrBMaxCpbltyTrqRcvd_write_IRV: accessed-variable=VeMTIR_b_MtrBMaxCpbltyTrqRcvd_write_IRV
        PokeMTIR_M_MtrBCapabilityMin
          written-local-variables:
            access WV_VaMTIR_M_MtrBMinCpbltyTrq_Poke_Init_IRV: accessed-variable=VaMTIR_M_MtrBMinCpbltyTrq_Poke_Init_IRV
            access WV_VeMTIR_b_MtrBMinCpbltyRcvd_write_IRV: accessed-variable=VeMTIR_b_MtrBMinCpbltyRcvd_write_IRV
        PokeMTIR_M_MtrBMaxTrqLmt_TCM
          data-send-points:
            access OUT_VeMTIR_M_MtrBMaxTrqLmt_TCM_Value: accessed-variable=VeMTIR_M_MtrBMaxTrqLmt_TCM.Value
            access OUT_VeMTIR_M_MtrBMaxTrqLmt_TCMFA_Value: accessed-variable=VeMTIR_M_MtrBMaxTrqLmt_TCMFA.Value
          written-local-variables:
            access WV_VeMTIR_M_MtrBMaxTrqLmt_TCM_write_IRV: accessed-variable=VeMTIR_M_MtrBMaxTrqLmt_TCM_write_IRV
        PokeMTIR_M_MtrBMinTrqLmt_TCM
          data-send-points:
            access OUT_VeMTIR_M_MtrBMinTrqLmt_TCM_Value: accessed-variable=VeMTIR_M_MtrBMinTrqLmt_TCM.Value
            access OUT_VeMTIR_M_MtrBMinTrqLmt_TCMFA_Value: accessed-variable=VeMTIR_M_MtrBMinTrqLmt_TCMFA.Value
          written-local-variables:
            access WV_VeMTIR_M_MtrBMinTrqLmt_TCM_write_IRV: accessed-variable=VeMTIR_M_MtrBMinTrqLmt_TCM_write_IRV
        PokeMTIR_M_MtrB_MaxTorq
          written-local-variables:
            access WV_VeMTIR_M_MtrB_MaxTorq_write_IRV: accessed-variable=VeMTIR_M_MtrB_MaxTorq_write_IRV
            access WV_VeMTIR_b_MtrB_MaxTorqSgnl_Rcvd_write_IRV: accessed-variable=VeMTIR_b_MtrB_MaxTorqSgnl_Rcvd_write_IRV
        PokeMTIR_M_MtrB_MinTorq
          written-local-variables:
            access WV_VeMTIR_M_MtrB_MinTorq_write_IRV: accessed-variable=VeMTIR_M_MtrB_MinTorq_write_IRV
            access WV_VeMTIR_b_MtrB_MinTorqSgnl_Rcvd_write_IRV: accessed-variable=VeMTIR_b_MtrB_MinTorqSgnl_Rcvd_write_IRV
        PokeMTIR_M_MtrB_TorqAchieved
          written-local-variables:
            access WV_VeMTIR_M_MtrB_TorqAchieved_write_IRV: accessed-variable=VeMTIR_M_MtrB_TorqAchieved_write_IRV
            access WV_VeMTIR_b_MtrB_TorqAchievedFA_write_IRV: accessed-variable=VeMTIR_b_MtrB_TorqAchievedFA_write_IRV
            access WV_VeMTIR_b_MtrB_TorqAchievedSgnl_Rcvd_write_IRV: accessed-variable=VeMTIR_b_MtrB_TorqAchievedSgnl_Rcvd_write_IRV
        PokeMTIR_M_MtrB_TorqAchieved_AEMD
          written-local-variables:
            access WV_VeMTIR_M_MtrB_TorqAchieved_AEMD_write_IRV: accessed-variable=VeMTIR_M_MtrB_TorqAchieved_AEMD_write_IRV
            access WV_VeMTIR_b_MtrB_TorqAchieved_AEMDFA_write_IRV: accessed-variable=VeMTIR_b_MtrB_TorqAchieved_AEMDFA_write_IRV
            access WV_VeMTIR_b_MtrB_TorqAchieved_AEMDSgnl_Rcvd_write_IRV: accessed-variable=VeMTIR_b_MtrB_TorqAchieved_AEMDSgnl_Rcvd_write_IRV
        PokeMTIR_M_MtrCCapabilityMax
        PokeMTIR_M_MtrCCapabilityMin
        PokeMTIR_M_MtrC_MaxTorq
        PokeMTIR_M_MtrC_MinTorq
        PokeMTIR_M_MtrC_TorqAchieved
          written-local-variables:
            access WV_VeMTIR_b_MtrC_TorqAchievedSgnl_Rcvd_write_IRV: accessed-variable=VeMTIR_b_MtrC_TorqAchievedSgnl_Rcvd_write_IRV
        PokeMTIR_M_MtrC_TorqAchieved_AEMD
          written-local-variables:
            access WV_VeMTIR_b_MtrC_TorqAchieved_AEMDSgnl_Rcvd_write_IRV: accessed-variable=VeMTIR_b_MtrC_TorqAchieved_AEMDSgnl_Rcvd_write_IRV
        PokeMTIR_M_P2SpdCntrlMaxTrqLmt
          written-local-variables:
            access WV_VeMTIR_M_P2SpdCntrlMaxTrqLmt_Init_IRV: accessed-variable=VeMTIR_M_P2SpdCntrlMaxTrqLmt_Init_IRV
        PokeMTIR_M_P2SpdCntrlMinTrqLmt
          written-local-variables:
            access WV_VeMTIR_M_P2SpdCntrlMinTrqLmt_Init_IRV: accessed-variable=VeMTIR_M_P2SpdCntrlMinTrqLmt_Init_IRV
        PokeMTIR_k_MtrADeratingFactor
          written-local-variables:
            access WV_VeMTIR_b_MtrADrtngFctrRcvd_write_IRV: accessed-variable=VeMTIR_b_MtrADrtngFctrRcvd_write_IRV
            access WV_VeMTIR_k_MtrADrtngFctr_Poke_Init_IRV: accessed-variable=VeMTIR_k_MtrADrtngFctr_Poke_Init_IRV
        PokeMTIR_k_MtrBDeratingFactor
          written-local-variables:
            access WV_VeMTIR_b_MtrBDrtngFctrRcvd_write_IRV: accessed-variable=VeMTIR_b_MtrBDrtngFctrRcvd_write_IRV
            access WV_VeMTIR_k_MtrBDrtngFctr_Init_IRV: accessed-variable=VeMTIR_k_MtrBDrtngFctr_Init_IRV
        PokeMTIR_k_MtrCDeratingFactor
        PokeMTIR_n_MtrACapabilitySpd
          written-local-variables:
            access WV_VaMTIR_n_MtrACpbltySpd_Poke_Init_IRV: accessed-variable=VaMTIR_n_MtrACpbltySpd_Poke_Init_IRV
            access WV_VeMTIR_b_MtrACpbltySpdRcvd_write_IRV: accessed-variable=VeMTIR_b_MtrACpbltySpdRcvd_write_IRV
        PokeMTIR_n_MtrBCapabilitySpd
          written-local-variables:
            access WV_VaMTIR_n_MtrBCpbltySpd_Poke_Init_IRV: accessed-variable=VaMTIR_n_MtrBCpbltySpd_Poke_Init_IRV
            access WV_VeMTIR_b_MtrBCpbltySpdRcvd_write_IRV: accessed-variable=VeMTIR_b_MtrBCpbltySpdRcvd_write_IRV
        PokeMTIR_n_MtrCCapabilitySpd
        TmotMTIR_M_MtrACapabilityMax
          written-local-variables:
            access WV_VeMTIR_b_MtrAMaxCpbltyTrqRcvd_write_IRV: accessed-variable=VeMTIR_b_MtrAMaxCpbltyTrqRcvd_write_IRV
        TmotMTIR_M_MtrACapabilityMin
          written-local-variables:
            access WV_VeMTIR_b_MtrAMinCpbltyTrqRcvd_write_IRV: accessed-variable=VeMTIR_b_MtrAMinCpbltyTrqRcvd_write_IRV
        TmotMTIR_M_MtrBCapabilityMax
          written-local-variables:
            access WV_VeMTIR_b_MtrBMaxCpbltyTrqRcvd_write_IRV: accessed-variable=VeMTIR_b_MtrBMaxCpbltyTrqRcvd_write_IRV
        TmotMTIR_M_MtrBCapabilityMin
          written-local-variables:
            access WV_VeMTIR_b_MtrBMinCpbltyRcvd_write_IRV: accessed-variable=VeMTIR_b_MtrBMinCpbltyRcvd_write_IRV
        TmotMTIR_M_MtrCCapabilityMax
        TmotMTIR_M_MtrCCapabilityMin
        TmotMTIR_b_MtrA_MaxTorq
          written-local-variables:
            access WV_VeMTIR_b_MtrA_MaxTorqSgnl_Rcvd_write_IRV: accessed-variable=VeMTIR_b_MtrA_MaxTorqSgnl_Rcvd_write_IRV
        TmotMTIR_b_MtrA_MinTorq
          written-local-variables:
            access WV_VeMTIR_b_MtrA_MinTorqSgnl_Rcvd_write_IRV: accessed-variable=VeMTIR_b_MtrA_MinTorqSgnl_Rcvd_write_IRV
        TmotMTIR_b_MtrA_TorqAchieved
          written-local-variables:
            access WV_VeMTIR_b_MtrA_TorqAchievedSgnl_Rcvd_write_IRV: accessed-variable=VeMTIR_b_MtrA_TorqAchievedSgnl_Rcvd_write_IRV
        TmotMTIR_b_MtrA_TorqAchieved_AEMD
          written-local-variables:
            access WV_VeMTIR_b_MtrA_TorqAchieved_AEMDSgnl_Rcvd_write_IRV: accessed-variable=VeMTIR_b_MtrA_TorqAchieved_AEMDSgnl_Rcvd_write_IRV
        TmotMTIR_b_MtrB_MaxTorq
          written-local-variables:
            access WV_VeMTIR_b_MtrB_MaxTorqSgnl_Rcvd_write_IRV: accessed-variable=VeMTIR_b_MtrB_MaxTorqSgnl_Rcvd_write_IRV
        TmotMTIR_b_MtrB_MinTorq
          written-local-variables:
            access WV_VeMTIR_b_MtrB_MinTorqSgnl_Rcvd_write_IRV: accessed-variable=VeMTIR_b_MtrB_MinTorqSgnl_Rcvd_write_IRV
        TmotMTIR_b_MtrB_TorqAchieved
          written-local-variables:
            access WV_VeMTIR_b_MtrB_TorqAchievedSgnl_Rcvd_write_IRV: accessed-variable=VeMTIR_b_MtrB_TorqAchievedSgnl_Rcvd_write_IRV
        TmotMTIR_b_MtrB_TorqAchieved_AEMD
          written-local-variables:
            access WV_VeMTIR_b_MtrB_TorqAchieved_AEMDSgnl_Rcvd_write_IRV: accessed-variable=VeMTIR_b_MtrB_TorqAchieved_AEMDSgnl_Rcvd_write_IRV
        TmotMTIR_b_MtrC_MaxTorq
        TmotMTIR_b_MtrC_MinTorq
        TmotMTIR_b_MtrC_TorqAchieved
          written-local-variables:
            access WV_VeMTIR_b_MtrC_TorqAchievedSgnl_Rcvd_write_IRV: accessed-variable=VeMTIR_b_MtrC_TorqAchievedSgnl_Rcvd_write_IRV
        TmotMTIR_b_MtrC_TorqAchieved_AEMD
          written-local-variables:
            access WV_VeMTIR_b_MtrC_TorqAchieved_AEMDSgnl_Rcvd_write_IRV: accessed-variable=VeMTIR_b_MtrC_TorqAchieved_AEMDSgnl_Rcvd_write_IRV
        TmotMTIR_k_MtrADeratingFactor
          written-local-variables:
            access WV_VeMTIR_b_MtrADrtngFctrRcvd_write_IRV: accessed-variable=VeMTIR_b_MtrADrtngFctrRcvd_write_IRV
        TmotMTIR_k_MtrBDeratingFactor
          written-local-variables:
            access WV_VeMTIR_b_MtrBDrtngFctrRcvd_write_IRV: accessed-variable=VeMTIR_b_MtrBDrtngFctrRcvd_write_IRV
        TmotMTIR_k_MtrCDeratingFactor
        TmotMTIR_n_MtrACapabilitySpd
          written-local-variables:
            access WV_VeMTIR_b_MtrACpbltySpdRcvd_write_IRV: accessed-variable=VeMTIR_b_MtrACpbltySpdRcvd_write_IRV
        TmotMTIR_n_MtrBCapabilitySpd
          written-local-variables:
            access WV_VeMTIR_b_MtrBCpbltySpdRcvd_write_IRV: accessed-variable=VeMTIR_b_MtrBCpbltySpdRcvd_write_IRV
        TmotMTIR_n_MtrCCapabilitySpd
      variation point proxy Variant_MTIR_1: category=CONDITION, condition-access=0
